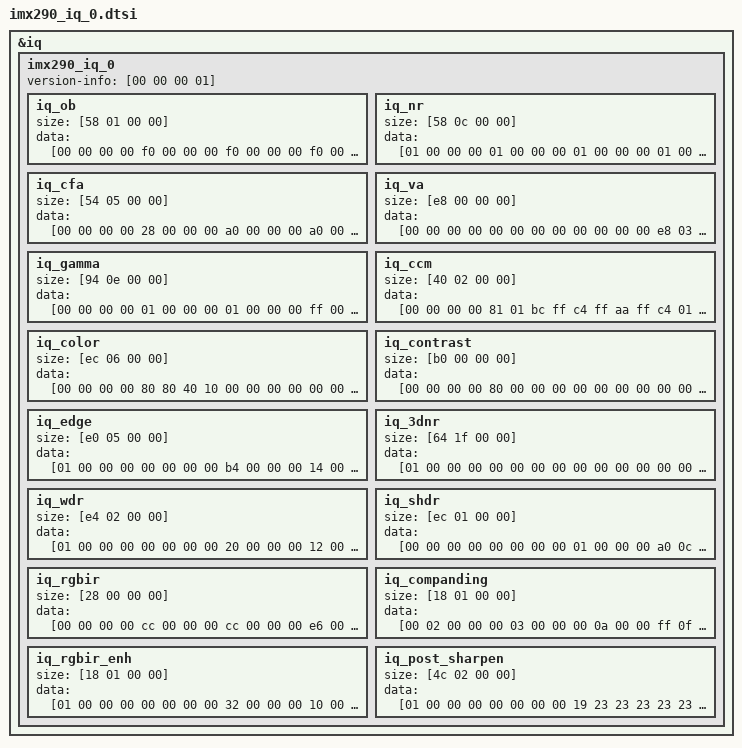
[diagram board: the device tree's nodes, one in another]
/*
 * Novatek Ltd. NVT9856x ISP part of dts
 */

&iq {
	imx290_iq_0 {
		version-info = [00 00 00 01];
		iq_ob {
			size = [58 01 00 00];
			data = [00 00 00 00 f0 00 00 00 f0 00 00 00 f0 00 00 00 f0 00 00 00 f0 00 00 00 f0 00 00 00 f0 00 00 00 f0 00 00 00 f0 00 00 00 f0 00 00 00 f0 00 00 00 f0 00 00 00 f0 00 00 00 f0 00 00 00 f0 00 00 00 f0 00 00 00 f0 00 00 00 f0 00 00 00 f0 00 00 00 f0 00 00 00 f0 00 00 00 f0 00 00 00 f0 00 00 00 f0 00 00 00 f0 00 00 00 f0 00 00 00 f0 00 00 00 f0 00 00 00 f0 00 00 00 f0 00 00 00 f0 00 00 00 f0 00 00 00 f0 00 00 00 f0 00 00 00 f0 00 00 00 f0 00 00 00 f0 00 00 00 f0 00 00 00 f0 00 00 00 f0 00 00 00 f0 00 00 00 f0 00 00 00 f0 00 00 00 f0 00 00 00 f0 00 00 00 f0 00 00 00 f0 00 00 00 f0 00 00 00 f0 00 00 00 f0 00 00 00 f0 00 00 00 f0 00 00 00 f0 00 00 00 f0 00 00 00 f0 00 00 00 f0 00 00 00 f0 00 00 00 f0 00 00 00 f0 00 00 00 f0 00 00 00 f0 00 00 00 f0 00 00 00 f0 00 00 00 f0 00 00 00 f0 00 00 00 f0 00 00 00 f0 00 00 00 f0 00 00 00 f0 00 00 00 f0 00 00 00 f0 00 00 00 f0 00 00 00 f0 00 00 00 f0 00 00 00 f0 00 00 00 f0 00 00 00 f0 00 00 00 f0 00 00 00 f0 00 00 00 f0 00 00 00 f0 00 00 00 f0 00 00 00 f0 00 00 00 f0 00 00 00 f0 00 00 00];
		};
		iq_nr {
			size = [58 0c 00 00];
			data = [01 00 00 00 01 00 00 00 01 00 00 00 01 00 00 00 01 00 00 00 00 00 00 00 00 00 00 00 00 01 00 00 00 00 00 00 ff 0f 00 00 ff 0f 00 00 ff 0f 00 00 ff 0f 00 00 ff 0f 00 00 ff 0f 00 00 ff 0f 00 00 ff 0f 00 00 ff 0f 00 00 ff 0f 00 00 00 01 80 00 00 00 00 00 00 00 00 00 00 00 00 00 00 00 00 00 00 00 00 00 00 00 00 00 00 00 00 00 00 00 00 00 00 00 00 00 00 00 00 00 00 00 00 00 00 00 00 00 00 00 00 00 00 00 00 00 00 00 00 00 00 00 00 00 00 00 00 00 00 00 00 00 00 00 00 00 00 00 00 00 00 00 00 00 00 00 00 00 00 00 00 00 00 00 00 00 00 00 00 00 80 00 00 00 00 00 00 00 00 00 00 00 00 00 00 00 00 00 00 00 00 00 00 00 00 00 00 00 02 00 00 00 02 00 00 00 00 00 00 00 c6 02 00 00 0c 04 00 00 af 06 00 00 3d 09 00 00 41 0f 00 00 c6 02 00 00 0c 04 00 00 af 06 00 00 3d 09 00 00 41 0f 00 00 00 00 80 00 00 00 00 00 00 00 00 00 00 00 00 00 00 00 00 00 00 00 00 00 00 00 00 00 00 00 00 00 00 00 00 00 00 00 00 00 00 00 00 00 00 00 00 00 00 00 00 00 00 00 00 00 00 00 00 00 00 00 00 00 00 00 00 00 00 00 00 00 00 00 00 00 00 00 00 00 00 00 00 00 00 00 00 00 00 00 00 00 00 00 00 00 00 00 00 00 00 00 00 00 80 00 00 00 08 00 00 00 08 00 00 00 08 00 00 00 08 00 00 00 00 00 00 00 04 00 00 00 00 00 00 00 00 00 00 00 00 00 00 00 c6 02 00 00 0c 04 00 00 af 06 00 00 3d 09 00 00 41 0f 00 00 c6 02 00 00 0c 04 00 00 af 06 00 00 3d 09 00 00 41 0f 00 00 00 00 80 00 00 00 00 00 00 00 00 00 01 00 00 00 01 00 00 00 01 00 00 00 02 00 00 00 00 00 00 00 00 00 00 00 01 00 00 00 01 00 00 00 01 00 00 00 01 00 00 00 01 00 00 00 02 00 00 00 02 00 00 00 02 00 00 00 02 00 00 00 02 00 00 00 02 00 00 00 02 00 00 00 02 00 00 00 03 00 00 00 03 00 00 00 00 00 00 00 00 00 00 00 80 00 00 00 08 00 00 00 08 00 00 00 08 00 00 00 08 00 00 00 00 00 00 00 04 00 00 00 00 00 00 00 00 00 00 00 00 00 00 00 c6 02 00 00 0c 04 00 00 af 06 00 00 3d 09 00 00 41 0f 00 00 c6 02 00 00 0c 04 00 00 af 06 00 00 3d 09 00 00 41 0f 00 00 00 00 80 00 00 00 00 00 01 00 00 00 02 00 00 00 03 00 00 00 03 00 00 00 04 00 00 00 00 00 00 00 01 00 00 00 02 00 00 00 02 00 00 00 03 00 00 00 03 00 00 00 03 00 00 00 04 00 00 00 04 00 00 00 04 00 00 00 05 00 00 00 05 00 00 00 05 00 00 00 05 00 00 00 05 00 00 00 06 00 00 00 06 00 00 00 00 00 00 00 00 00 00 00 80 00 00 00 08 00 00 00 08 00 00 00 08 00 00 00 08 00 00 00 00 00 00 00 04 00 00 00 00 00 00 00 00 00 00 00 00 00 00 00 c6 02 00 00 0c 04 00 00 af 06 00 00 3d 09 00 00 41 0f 00 00 c6 02 00 00 0c 04 00 00 af 06 00 00 3d 09 00 00 41 0f 00 00 00 00 80 00 00 00 00 00 01 00 00 00 02 00 00 00 03 00 00 00 03 00 00 00 04 00 00 00 00 00 00 00 01 00 00 00 02 00 00 00 02 00 00 00 03 00 00 00 03 00 00 00 03 00 00 00 04 00 00 00 04 00 00 00 04 00 00 00 05 00 00 00 05 00 00 00 05 00 00 00 05 00 00 00 05 00 00 00 06 00 00 00 06 00 00 00 00 00 00 00 00 00 00 00 80 00 00 00 08 00 00 00 08 00 00 00 08 00 00 00 08 00 00 00 00 00 00 00 08 00 00 00 00 00 00 00 00 00 00 00 00 00 00 00 c6 02 00 00 0c 04 00 00 af 06 00 00 3d 09 00 00 41 0f 00 00 c6 02 00 00 0c 04 00 00 af 06 00 00 3d 09 00 00 41 0f 00 00 00 00 80 00 00 00 00 00 02 00 00 00 03 00 00 00 04 00 00 00 04 00 00 00 06 00 00 00 00 00 00 00 01 00 00 00 02 00 00 00 02 00 00 00 03 00 00 00 03 00 00 00 03 00 00 00 04 00 00 00 04 00 00 00 04 00 00 00 05 00 00 00 05 00 00 00 05 00 00 00 05 00 00 00 05 00 00 00 06 00 00 00 06 00 00 00 00 00 00 00 10 00 00 00 80 00 00 00 08 00 00 00 08 00 00 00 08 00 00 00 08 00 00 00 00 00 00 00 0c 00 00 00 00 00 00 00 00 00 00 00 00 00 00 00 c6 02 00 00 0c 04 00 00 af 06 00 00 3d 09 00 00 41 0f 00 00 c6 02 00 00 0c 04 00 00 af 06 00 00 3d 09 00 00 41 0f 00 00 00 00 80 00 00 00 00 00 03 00 00 00 04 00 00 00 06 00 00 00 07 00 00 00 09 00 00 00 00 00 00 00 02 00 00 00 03 00 00 00 04 00 00 00 05 00 00 00 06 00 00 00 06 00 00 00 07 00 00 00 07 00 00 00 08 00 00 00 08 00 00 00 09 00 00 00 09 00 00 00 0a 00 00 00 0a 00 00 00 0a 00 00 00 0b 00 00 00 00 00 00 00 10 00 00 00 80 00 00 00 08 00 00 00 08 00 00 00 08 00 00 00 08 00 00 00 00 00 00 00 10 00 00 00 00 00 00 00 00 00 00 00 00 00 00 00 c6 02 00 00 0c 04 00 00 af 06 00 00 3d 09 00 00 41 0f 00 00 c6 02 00 00 0c 04 00 00 af 06 00 00 3d 09 00 00 41 0f 00 00 00 00 80 00 00 00 00 00 07 00 00 00 09 00 00 00 0c 00 00 00 0e 00 00 00 13 00 00 00 00 00 00 00 05 00 00 00 07 00 00 00 09 00 00 00 0a 00 00 00 0b 00 00 00 0c 00 00 00 0d 00 00 00 0e 00 00 00 0f 00 00 00 10 00 00 00 11 00 00 00 12 00 00 00 12 00 00 00 13 00 00 00 14 00 00 00 14 00 00 00 00 00 00 00 10 00 00 00 80 00 00 00 08 00 00 00 08 00 00 00 08 00 00 00 08 00 00 00 00 00 00 00 12 00 00 00 00 00 00 00 00 00 00 00 00 00 00 00 c6 02 00 00 0c 04 00 00 af 06 00 00 3d 09 00 00 41 0f 00 00 c6 02 00 00 0c 04 00 00 af 06 00 00 3d 09 00 00 41 0f 00 00 00 00 80 00 00 00 00 00 0b 00 00 00 10 00 00 00 14 00 00 00 17 00 00 00 21 00 00 00 00 00 00 00 08 00 00 00 0b 00 00 00 0d 00 00 00 10 00 00 00 11 00 00 00 13 00 00 00 15 00 00 00 16 00 00 00 18 00 00 00 19 00 00 00 1a 00 00 00 1b 00 00 00 1c 00 00 00 1d 00 00 00 1e 00 00 00 20 00 00 00 00 00 00 00 10 00 00 00 80 00 00 00 08 00 00 00 08 00 00 00 08 00 00 00 08 00 00 00 00 00 00 00 12 00 00 00 00 00 00 00 00 00 00 00 00 00 00 00 c6 02 00 00 0c 04 00 00 af 06 00 00 3d 09 00 00 41 0f 00 00 c6 02 00 00 0c 04 00 00 af 06 00 00 3d 09 00 00 41 0f 00 00 2c 01 2c 01 00 00 00 00 20 00 00 00 2d 00 00 00 38 00 00 00 40 00 00 00 5b 00 00 00 00 00 00 00 16 00 00 00 1f 00 00 00 26 00 00 00 2c 00 00 00 31 00 00 00 35 00 00 00 3a 00 00 00 3e 00 00 00 42 00 00 00 45 00 00 00 48 00 00 00 4c 00 00 00 4f 00 00 00 52 00 00 00 55 00 00 00 58 00 00 00 08 00 00 00 12 00 00 00 80 00 00 00 08 00 00 00 08 00 00 00 08 00 00 00 08 00 00 00 00 00 00 00 14 00 00 00 00 00 00 00 00 00 00 00 00 00 00 00 c6 02 00 00 0c 04 00 00 af 06 00 00 3d 09 00 00 41 0f 00 00 c6 02 00 00 0c 04 00 00 af 06 00 00 3d 09 00 00 41 0f 00 00 00 00 80 00 00 00 00 00 31 00 00 00 46 00 00 00 56 00 00 00 63 00 00 00 8d 00 00 00 00 00 00 00 22 00 00 00 30 00 00 00 3a 00 00 00 44 00 00 00 4c 00 00 00 53 00 00 00 59 00 00 00 60 00 00 00 66 00 00 00 6b 00 00 00 70 00 00 00 75 00 00 00 7a 00 00 00 7f 00 00 00 83 00 00 00 88 00 00 00 0f 00 00 00 12 00 00 00 80 00 00 00 08 00 00 00 08 00 00 00 08 00 00 00 08 00 00 00 00 00 00 00 18 00 00 00 00 00 00 00 00 00 00 00 00 00 00 00 c6 02 00 00 0c 04 00 00 af 06 00 00 3d 09 00 00 41 0f 00 00 c6 02 00 00 0c 04 00 00 af 06 00 00 3d 09 00 00 41 0f 00 00 00 00 80 00 00 00 00 00 43 00 00 00 5f 00 00 00 75 00 00 00 87 00 00 00 bf 00 00 00 00 00 00 00 30 00 00 00 43 00 00 00 53 00 00 00 60 00 00 00 6b 00 00 00 75 00 00 00 7e 00 00 00 87 00 00 00 90 00 00 00 97 00 00 00 9f 00 00 00 a6 00 00 00 ad 00 00 00 b3 00 00 00 b9 00 00 00 c0 00 00 00 0f 00 00 00 12 00 00 00 80 00 00 00 08 00 00 00 08 00 00 00 08 00 00 00 08 00 00 00 00 00 00 00 1a 00 00 00 01 00 00 00 02 00 00 00 00 00 00 00 c6 02 00 00 0c 04 00 00 af 06 00 00 3d 09 00 00 41 0f 00 00 c6 02 00 00 0c 04 00 00 af 06 00 00 3d 09 00 00 41 0f 00 00 00 00 80 00 00 00 00 00 5e 00 00 00 85 00 00 00 a3 00 00 00 bc 00 00 00 0a 01 00 00 00 00 00 00 40 00 00 00 5a 00 00 00 6e 00 00 00 80 00 00 00 8f 00 00 00 9c 00 00 00 a9 00 00 00 b5 00 00 00 c0 00 00 00 ca 00 00 00 d4 00 00 00 dd 00 00 00 e6 00 00 00 ef 00 00 00 f7 00 00 00 00 01 00 00 0f 00 00 00 00 00 00 00 80 00 00 00 08 00 00 00 08 00 00 00 08 00 00 00 08 00 00 00 00 00 00 00 1c 00 00 00 02 00 00 00 03 00 00 00 00 00 00 00 c6 02 00 00 0c 04 00 00 af 06 00 00 3d 09 00 00 41 0f 00 00 c6 02 00 00 0c 04 00 00 af 06 00 00 3d 09 00 00 41 0f 00 00 09 00 80 00 00 00 00 00 2e 00 00 00 42 00 00 00 51 00 00 00 5d 00 00 00 84 00 00 00 00 00 00 00 32 00 00 00 47 00 00 00 57 00 00 00 65 00 00 00 71 00 00 00 7c 00 00 00 86 00 00 00 8f 00 00 00 98 00 00 00 a0 00 00 00 a8 00 00 00 af 00 00 00 b7 00 00 00 be 00 00 00 c4 00 00 00 cb 00 00 00 00 00 00 00 20 00 00 00 20 00 00 00 10 00 00 00 10 00 00 00 10 00 00 00 10 00 00 00 1c 00 00 00 16 00 00 00 01 00 00 00 01 00 00 00 00 00 00 00 c6 02 00 00 0c 04 00 00 af 06 00 00 3d 09 00 00 41 0f 00 00 c6 02 00 00 0c 04 00 00 af 06 00 00 3d 09 00 00 41 0f 00 00 09 00 80 00 00 00 00 00 2e 00 00 00 42 00 00 00 51 00 00 00 5d 00 00 00 84 00 00 00 00 00 00 00 32 00 00 00 47 00 00 00 57 00 00 00 65 00 00 00 71 00 00 00 7c 00 00 00 86 00 00 00 8f 00 00 00 98 00 00 00 a0 00 00 00 a8 00 00 00 af 00 00 00 b7 00 00 00 be 00 00 00 c4 00 00 00 cb 00 00 00 00 00 00 00 20 00 00 00 20 00 00 00 10 00 00 00 10 00 00 00 10 00 00 00 10 00 00 00 1c 00 00 00 16 00 00 00 01 00 00 00 01 00 00 00 00 00 00 00 c6 02 00 00 0c 04 00 00 af 06 00 00 3d 09 00 00 41 0f 00 00 c6 02 00 00 0c 04 00 00 af 06 00 00 3d 09 00 00 41 0f 00 00 09 00 80 00 00 00 00 00 2e 00 00 00 42 00 00 00 51 00 00 00 5d 00 00 00 84 00 00 00 00 00 00 00 32 00 00 00 47 00 00 00 57 00 00 00 65 00 00 00 71 00 00 00 7c 00 00 00 86 00 00 00 8f 00 00 00 98 00 00 00 a0 00 00 00 a8 00 00 00 af 00 00 00 b7 00 00 00 be 00 00 00 c4 00 00 00 cb 00 00 00 00 00 00 00 20 00 00 00 20 00 00 00 10 00 00 00 10 00 00 00 10 00 00 00 10 00 00 00 1c 00 00 00 16 00 00 00 01 00 00 00 01 00 00 00 00 00 00 00 c6 02 00 00 0c 04 00 00 af 06 00 00 3d 09 00 00 41 0f 00 00 c6 02 00 00 0c 04 00 00 af 06 00 00 3d 09 00 00 41 0f 00 00 09 00 80 00 00 00 00 00 2e 00 00 00 42 00 00 00 51 00 00 00 5d 00 00 00 84 00 00 00 00 00 00 00 32 00 00 00 47 00 00 00 57 00 00 00 65 00 00 00 71 00 00 00 7c 00 00 00 86 00 00 00 8f 00 00 00 98 00 00 00 a0 00 00 00 a8 00 00 00 af 00 00 00 b7 00 00 00 be 00 00 00 c4 00 00 00 cb 00 00 00 00 00 00 00 20 00 00 00 20 00 00 00 10 00 00 00 10 00 00 00 10 00 00 00 10 00 00 00 1c 00 00 00 16 00 00 00 01 00 00 00 01 00 00 00];
		};
		iq_cfa {
			size = [54 05 00 00];
			data = [00 00 00 00 28 00 00 00 a0 00 00 00 a0 00 00 00 40 00 00 00 0f 00 00 00 0f 00 00 00 07 00 00 00 04 00 00 00 03 00 00 00 02 00 00 00 02 00 00 00 01 00 00 00 01 00 00 00 01 00 00 00 01 00 00 00 00 00 00 00 00 00 00 00 00 00 00 00 00 00 00 00 00 00 00 00 28 00 00 00 a0 00 00 00 a0 00 00 00 40 00 00 00 0f 00 00 00 0f 00 00 00 07 00 00 00 04 00 00 00 03 00 00 00 02 00 00 00 02 00 00 00 01 00 00 00 01 00 00 00 01 00 00 00 01 00 00 00 00 00 00 00 00 00 00 00 00 00 00 00 00 00 00 00 00 00 00 00 28 00 00 00 a0 00 00 00 a0 00 00 00 40 00 00 00 0f 00 00 00 0f 00 00 00 07 00 00 00 04 00 00 00 03 00 00 00 02 00 00 00 02 00 00 00 01 00 00 00 01 00 00 00 01 00 00 00 01 00 00 00 00 00 00 00 00 00 00 00 00 00 00 00 00 00 00 00 00 00 00 00 28 00 00 00 a0 00 00 00 a0 00 00 00 40 00 00 00 0f 00 00 00 0f 00 00 00 07 00 00 00 04 00 00 00 03 00 00 00 02 00 00 00 02 00 00 00 01 00 00 00 01 00 00 00 01 00 00 00 01 00 00 00 00 00 00 00 00 00 00 00 00 00 00 00 00 00 00 00 00 00 00 00 28 00 00 00 a0 00 00 00 a0 00 00 00 40 00 00 00 0f 00 00 00 0f 00 00 00 07 00 00 00 04 00 00 00 03 00 00 00 02 00 00 00 02 00 00 00 01 00 00 00 01 00 00 00 01 00 00 00 01 00 00 00 00 00 00 00 00 00 00 00 00 00 00 00 00 00 00 00 00 00 00 00 28 00 00 00 a0 00 00 00 a0 00 00 00 40 00 00 00 0f 00 00 00 0f 00 00 00 07 00 00 00 04 00 00 00 03 00 00 00 02 00 00 00 02 00 00 00 01 00 00 00 01 00 00 00 01 00 00 00 01 00 00 00 00 00 00 00 00 00 00 00 00 00 00 00 00 00 00 00 00 00 00 00 28 00 00 00 a0 00 00 00 a0 00 00 00 40 00 00 00 0f 00 00 00 0f 00 00 00 07 00 00 00 04 00 00 00 03 00 00 00 02 00 00 00 02 00 00 00 01 00 00 00 01 00 00 00 01 00 00 00 01 00 00 00 00 00 00 00 00 00 00 00 00 00 00 00 00 00 00 00 00 00 00 00 28 00 00 00 a0 00 00 00 a0 00 00 00 40 00 00 00 0f 00 00 00 0f 00 00 00 07 00 00 00 04 00 00 00 03 00 00 00 02 00 00 00 02 00 00 00 01 00 00 00 01 00 00 00 01 00 00 00 01 00 00 00 00 00 00 00 00 00 00 00 00 00 00 00 00 00 00 00 00 00 00 00 28 00 00 00 a0 00 00 00 a0 00 00 00 40 00 00 00 0f 00 00 00 0f 00 00 00 07 00 00 00 04 00 00 00 03 00 00 00 02 00 00 00 02 00 00 00 01 00 00 00 01 00 00 00 01 00 00 00 01 00 00 00 00 00 00 00 00 00 00 00 00 00 00 00 00 00 00 00 00 00 00 00 50 00 00 00 a0 00 00 00 40 01 00 00 40 00 00 00 0f 00 00 00 0f 00 00 00 07 00 00 00 04 00 00 00 03 00 00 00 02 00 00 00 02 00 00 00 01 00 00 00 01 00 00 00 01 00 00 00 01 00 00 00 00 00 00 00 00 00 00 00 00 00 00 00 00 00 00 00 00 00 00 00 78 00 00 00 a0 00 00 00 80 02 00 00 40 00 00 00 0f 00 00 00 0f 00 00 00 07 00 00 00 04 00 00 00 03 00 00 00 02 00 00 00 02 00 00 00 01 00 00 00 01 00 00 00 01 00 00 00 01 00 00 00 00 00 00 00 00 00 00 00 00 00 00 00 00 00 00 00 00 00 00 00 78 00 00 00 a0 00 00 00 80 02 00 00 20 00 00 00 08 00 00 00 08 00 00 00 03 00 00 00 02 00 00 00 01 00 00 00 01 00 00 00 01 00 00 00 00 00 00 00 00 00 00 00 00 00 00 00 00 00 00 00 00 00 00 00 00 00 00 00 00 00 00 00 00 00 00 00 00 00 00 00 78 00 00 00 a0 00 00 00 80 02 00 00 20 00 00 00 08 00 00 00 08 00 00 00 03 00 00 00 02 00 00 00 01 00 00 00 01 00 00 00 01 00 00 00 00 00 00 00 00 00 00 00 00 00 00 00 00 00 00 00 00 00 00 00 00 00 00 00 00 00 00 00 00 00 00 00 00 00 00 00 78 00 00 00 a0 00 00 00 80 02 00 00 20 00 00 00 08 00 00 00 08 00 00 00 03 00 00 00 02 00 00 00 01 00 00 00 01 00 00 00 01 00 00 00 00 00 00 00 00 00 00 00 00 00 00 00 00 00 00 00 00 00 00 00 00 00 00 00 00 00 00 00 00 00 00 00 00 00 00 00 78 00 00 00 a0 00 00 00 80 02 00 00 20 00 00 00 08 00 00 00 08 00 00 00 03 00 00 00 02 00 00 00 01 00 00 00 01 00 00 00 01 00 00 00 00 00 00 00 00 00 00 00 00 00 00 00 00 00 00 00 00 00 00 00 00 00 00 00 00 00 00 00 00 00 00 00 00 00 00 00 78 00 00 00 a0 00 00 00 80 02 00 00 20 00 00 00 08 00 00 00 08 00 00 00 03 00 00 00 02 00 00 00 01 00 00 00 01 00 00 00 01 00 00 00 00 00 00 00 00 00 00 00 00 00 00 00 00 00 00 00 00 00 00 00 00 00 00 00 00 00 00 00 00 00 00 00 00 00 00 00 78 00 00 00 a0 00 00 00 80 02 00 00 20 00 00 00 08 00 00 00 08 00 00 00 03 00 00 00 02 00 00 00 01 00 00 00 01 00 00 00 01 00 00 00 00 00 00 00 00 00 00 00 00 00 00 00 00 00 00 00 00 00 00 00 00 00 00 00 00 00 00 00 00 00 00 00 00 00 00 00];
		};
		iq_va {
			size = [e8 00 00 00];
			data = [00 00 00 00 00 00 00 00 00 00 00 00 e8 03 00 00 e8 03 00 00 00 00 00 00 00 00 00 00 e8 03 00 00 e8 03 00 00 00 00 00 00 00 00 00 00 e8 03 00 00 e8 03 00 00 00 00 00 00 00 00 00 00 e8 03 00 00 e8 03 00 00 00 00 00 00 00 00 00 00 e8 03 00 00 e8 03 00 00 02 ff 00 00 03 02 00 ff 00 03 06 00 08 00 06 00 08 00 06 00 08 00 06 00 08 00 06 00 08 00 06 00 08 00 06 00 08 00 06 00 08 00 06 00 08 00 06 00 08 00 06 00 08 00 06 00 08 00 06 00 08 00 06 00 08 00 06 00 08 00 06 00 08 00 06 00 08 00 06 00 08 00 06 00 08 00 06 00 08 00 06 00 08 00 06 00 08 00 06 00 08 00 06 00 08 00 06 00 08 00 06 00 08 00 06 00 08 00 06 00 08 00 06 00 08 00 06 00 08 00 06 00 08 00 06 00 08 00 06 00 08 00 06 00 08 00 00 00];
		};
		iq_gamma {
			size = [94 0e 00 00];
			data = [00 00 00 00 01 00 00 00 01 00 00 00 ff 00 00 00 ff 00 00 00 ff 00 00 00 ff 00 00 00 ff 00 00 00 ff 00 00 00 ff 00 00 00 ff 00 00 00 ff 00 00 00 ff 00 00 00 ff 00 00 00 ff 00 00 00 ff 00 00 00 ff 00 00 00 ff 00 00 00 ff 00 00 00 ff 00 00 00 00 00 00 00 08 00 00 00 10 00 00 00 18 00 00 00 1c 00 00 00 20 00 00 00 24 00 00 00 26 00 00 00 28 00 00 00 29 00 00 00 2a 00 00 00 2b 00 00 00 2c 00 00 00 2d 00 00 00 2e 00 00 00 2f 00 00 00 30 00 00 00 31 00 00 00 32 00 00 00 33 00 00 00 34 00 00 00 35 00 00 00 36 00 00 00 37 00 00 00 38 00 00 00 39 00 00 00 3a 00 00 00 3b 00 00 00 3c 00 00 00 3d 00 00 00 3e 00 00 00 3f 00 00 00 03 00 00 00 03 00 00 00 03 00 00 00 02 00 00 00 02 00 00 00 02 00 00 00 01 00 00 00 01 00 00 00 00 00 00 00 00 00 00 00 00 00 00 00 00 00 00 00 00 00 00 00 00 00 00 00 00 00 00 00 00 00 00 00 00 00 00 00 00 00 00 00 00 00 00 00 00 00 00 00 00 00 00 00 00 00 00 00 00 00 00 00 00 00 00 00 00 00 00 00 00 00 00 00 00 00 00 00 00 00 00 00 00 00 00 00 00 00 00 00 00 00 00 00 00 00 00 00 00 00 00 00 10 00 00 00 20 00 00 00 30 00 00 00 40 00 00 00 50 00 00 00 60 00 00 00 70 00 00 00 80 00 00 00 90 00 00 00 a0 00 00 00 b0 00 00 00 c0 00 00 00 d0 00 00 00 e0 00 00 00 f0 00 00 00 00 01 00 00 10 01 00 00 20 01 00 00 30 01 00 00 40 01 00 00 50 01 00 00 60 01 00 00 70 01 00 00 80 01 00 00 a0 01 00 00 c0 01 00 00 e0 01 00 00 00 02 00 00 20 02 00 00 40 02 00 00 60 02 00 00 80 02 00 00 a0 02 00 00 c0 02 00 00 e0 02 00 00 00 03 00 00 40 03 00 00 80 03 00 00 c0 03 00 00 00 04 00 00 80 04 00 00 00 05 00 00 80 05 00 00 00 06 00 00 80 06 00 00 00 07 00 00 80 07 00 00 00 08 00 00 80 08 00 00 00 09 00 00 80 09 00 00 00 0a 00 00 80 0a 00 00 00 0b 00 00 80 0b 00 00 00 0c 00 00 80 0c 00 00 00 0d 00 00 80 0d 00 00 00 0e 00 00 80 0e 00 00 00 0f 00 00 80 0f 00 00 ff 0f 00 00 00 00 00 00 04 00 00 00 08 00 00 00 0c 00 00 00 10 00 00 00 14 00 00 00 18 00 00 00 1a 00 00 00 1c 00 00 00 1d 00 00 00 1e 00 00 00 1f 00 00 00 20 00 00 00 21 00 00 00 22 00 00 00 23 00 00 00 24 00 00 00 25 00 00 00 26 00 00 00 27 00 00 00 28 00 00 00 29 00 00 00 2a 00 00 00 2b 00 00 00 2c 00 00 00 2d 00 00 00 2e 00 00 00 2f 00 00 00 30 00 00 00 34 00 00 00 38 00 00 00 3c 00 00 00 02 00 00 00 02 00 00 00 02 00 00 00 02 00 00 00 02 00 00 00 02 00 00 00 01 00 00 00 01 00 00 00 00 00 00 00 00 00 00 00 00 00 00 00 00 00 00 00 00 00 00 00 00 00 00 00 00 00 00 00 00 00 00 00 00 00 00 00 00 00 00 00 00 00 00 00 00 00 00 00 00 00 00 00 00 00 00 00 00 00 00 00 00 00 00 00 00 00 00 00 00 00 00 00 00 00 00 00 00 00 00 00 02 00 00 00 02 00 00 00 02 00 00 00 02 00 00 00 05 00 00 00 00 00 00 00 00 00 00 00 80 00 00 00 f7 00 00 00 67 01 00 00 d0 01 00 00 30 02 00 00 82 02 00 00 be 02 00 00 f7 02 00 00 27 03 00 00 56 03 00 00 84 03 00 00 b2 03 00 00 de 03 00 00 09 04 00 00 33 04 00 00 5c 04 00 00 84 04 00 00 ac 04 00 00 d3 04 00 00 f9 04 00 00 1f 05 00 00 43 05 00 00 67 05 00 00 8b 05 00 00 d1 05 00 00 15 06 00 00 58 06 00 00 99 06 00 00 17 07 00 00 90 07 00 00 06 08 00 00 78 08 00 00 e7 08 00 00 54 09 00 00 be 09 00 00 26 0a 00 00 8d 0a 00 00 f1 0a 00 00 55 0b 00 00 b6 0b 00 00 17 0c 00 00 76 0c 00 00 d4 0c 00 00 32 0d 00 00 8e 0d 00 00 e9 0d 00 00 44 0e 00 00 9e 0e 00 00 b5 0e 00 00 cb 0e 00 00 e1 0e 00 00 f7 0e 00 00 0e 0f 00 00 24 0f 00 00 3a 0f 00 00 50 0f 00 00 66 0f 00 00 7c 0f 00 00 92 0f 00 00 a8 0f 00 00 be 0f 00 00 d4 0f 00 00 e9 0f 00 00 ff 0f 00 00 19 00 00 00 00 00 00 00 9e 00 00 00 2e 01 00 00 b1 01 00 00 2a 02 00 00 9a 02 00 00 01 03 00 00 63 03 00 00 be 03 00 00 14 04 00 00 65 04 00 00 b3 04 00 00 fc 04 00 00 41 05 00 00 84 05 00 00 c4 05 00 00 02 06 00 00 3a 06 00 00 71 06 00 00 a6 06 00 00 d9 06 00 00 09 07 00 00 38 07 00 00 64 07 00 00 8f 07 00 00 d3 07 00 00 16 08 00 00 57 08 00 00 96 08 00 00 0d 09 00 00 7d 09 00 00 e5 09 00 00 46 0a 00 00 a6 0a 00 00 02 0b 00 00 59 0b 00 00 ac 0b 00 00 fe 0b 00 00 4d 0c 00 00 9a 0c 00 00 e5 0c 00 00 2f 0d 00 00 77 0d 00 00 bd 0d 00 00 02 0e 00 00 45 0e 00 00 87 0e 00 00 c8 0e 00 00 08 0f 00 00 18 0f 00 00 28 0f 00 00 38 0f 00 00 48 0f 00 00 57 0f 00 00 67 0f 00 00 76 0f 00 00 85 0f 00 00 95 0f 00 00 a4 0f 00 00 b4 0f 00 00 c3 0f 00 00 d2 0f 00 00 e1 0f 00 00 f0 0f 00 00 ff 0f 00 00 32 00 00 00 00 00 00 00 e0 00 00 00 9e 01 00 00 43 02 00 00 d5 02 00 00 58 03 00 00 cf 03 00 00 3b 04 00 00 9e 04 00 00 fb 04 00 00 51 05 00 00 a1 05 00 00 ed 05 00 00 33 06 00 00 77 06 00 00 b7 06 00 00 f5 06 00 00 2c 07 00 00 61 07 00 00 95 07 00 00 c6 07 00 00 f4 07 00 00 21 08 00 00 4b 08 00 00 74 08 00 00 b3 08 00 00 f1 08 00 00 2d 09 00 00 67 09 00 00 d4 09 00 00 3a 0a 00 00 98 0a 00 00 ee 0a 00 00 44 0b 00 00 96 0b 00 00 e4 0b 00 00 2e 0c 00 00 76 0c 00 00 bc 0c 00 00 01 0d 00 00 43 0d 00 00 84 0d 00 00 c3 0d 00 00 01 0e 00 00 3e 0e 00 00 7a 0e 00 00 b4 0e 00 00 ed 0e 00 00 26 0f 00 00 34 0f 00 00 42 0f 00 00 4f 0f 00 00 5d 0f 00 00 6b 0f 00 00 79 0f 00 00 86 0f 00 00 94 0f 00 00 a2 0f 00 00 af 0f 00 00 bc 0f 00 00 ca 0f 00 00 d7 0f 00 00 e4 0f 00 00 f2 0f 00 00 ff 0f 00 00 4b 00 00 00 00 00 00 00 70 01 00 00 70 02 00 00 39 03 00 00 df 03 00 00 6d 04 00 00 ea 04 00 00 59 05 00 00 be 05 00 00 19 06 00 00 6d 06 00 00 ba 06 00 00 03 07 00 00 41 07 00 00 7d 07 00 00 b5 07 00 00 ec 07 00 00 1c 08 00 00 4b 08 00 00 78 08 00 00 a4 08 00 00 cd 08 00 00 f5 08 00 00 1b 09 00 00 41 09 00 00 7f 09 00 00 bb 09 00 00 f4 09 00 00 2a 0a 00 00 91 0a 00 00 f0 0a 00 00 47 0b 00 00 95 0b 00 00 e2 0b 00 00 2c 0c 00 00 72 0c 00 00 b4 0c 00 00 f4 0c 00 00 32 0d 00 00 6f 0d 00 00 a9 0d 00 00 e1 0d 00 00 18 0e 00 00 4d 0e 00 00 82 0e 00 00 b5 0e 00 00 e7 0e 00 00 17 0f 00 00 47 0f 00 00 53 0f 00 00 5f 0f 00 00 6a 0f 00 00 76 0f 00 00 82 0f 00 00 8e 0f 00 00 99 0f 00 00 a5 0f 00 00 b0 0f 00 00 bb 0f 00 00 c6 0f 00 00 d2 0f 00 00 dd 0f 00 00 e8 0f 00 00 f4 0f 00 00 ff 0f 00 00 64 00 00 00 00 00 00 00 00 02 00 00 43 03 00 00 2f 04 00 00 e9 04 00 00 83 05 00 00 06 06 00 00 78 06 00 00 de 06 00 00 37 07 00 00 89 07 00 00 d4 07 00 00 19 08 00 00 4f 08 00 00 83 08 00 00 b4 08 00 00 e4 08 00 00 0d 09 00 00 35 09 00 00 5c 09 00 00 82 09 00 00 a7 09 00 00 ca 09 00 00 ec 09 00 00 0e 0a 00 00 4c 0a 00 00 86 0a 00 00 bc 0a 00 00 ed 0a 00 00 4e 0b 00 00 a7 0b 00 00 f6 0b 00 00 3c 0c 00 00 81 0c 00 00 c2 0c 00 00 00 0d 00 00 3b 0d 00 00 73 0d 00 00 a9 0d 00 00 dd 0d 00 00 0f 0e 00 00 3e 0e 00 00 6d 0e 00 00 9a 0e 00 00 c6 0e 00 00 f0 0e 00 00 1a 0f 00 00 42 0f 00 00 69 0f 00 00 73 0f 00 00 7d 0f 00 00 86 0f 00 00 90 0f 00 00 9a 0f 00 00 a3 0f 00 00 ac 0f 00 00 b6 0f 00 00 bf 0f 00 00 c8 0f 00 00 d1 0f 00 00 db 0f 00 00 e4 0f 00 00 ed 0f 00 00 f6 0f 00 00 ff 0f 00 00 00 00 00 00 25 00 00 00 49 00 00 00 6b 00 00 00 8b 00 00 00 a9 00 00 00 c6 00 00 00 e1 00 00 00 f1 00 00 00 01 01 00 00 11 01 00 00 21 01 00 00 30 01 00 00 3e 01 00 00 4d 01 00 00 5b 01 00 00 68 01 00 00 75 01 00 00 82 01 00 00 8f 01 00 00 9b 01 00 00 a6 01 00 00 b1 01 00 00 bc 01 00 00 c7 01 00 00 d1 01 00 00 db 01 00 00 e4 01 00 00 ed 01 00 00 f6 01 00 00 fe 01 00 00 06 02 00 00 0d 02 00 00 14 02 00 00 1b 02 00 00 22 02 00 00 29 02 00 00 30 02 00 00 36 02 00 00 3d 02 00 00 44 02 00 00 4b 02 00 00 52 02 00 00 59 02 00 00 5f 02 00 00 66 02 00 00 6d 02 00 00 73 02 00 00 7a 02 00 00 80 02 00 00 87 02 00 00 8d 02 00 00 93 02 00 00 9a 02 00 00 a0 02 00 00 a6 02 00 00 ac 02 00 00 b3 02 00 00 b9 02 00 00 bf 02 00 00 c5 02 00 00 cb 02 00 00 d1 02 00 00 d7 02 00 00 dd 02 00 00 e3 02 00 00 e8 02 00 00 ee 02 00 00 f4 02 00 00 fa 02 00 00 ff 02 00 00 04 03 00 00 09 03 00 00 0e 03 00 00 13 03 00 00 18 03 00 00 1d 03 00 00 21 03 00 00 26 03 00 00 2b 03 00 00 30 03 00 00 35 03 00 00 3a 03 00 00 3e 03 00 00 43 03 00 00 48 03 00 00 4d 03 00 00 51 03 00 00 56 03 00 00 5b 03 00 00 5f 03 00 00 64 03 00 00 68 03 00 00 6d 03 00 00 72 03 00 00 76 03 00 00 7b 03 00 00 7f 03 00 00 84 03 00 00 88 03 00 00 8c 03 00 00 91 03 00 00 95 03 00 00 99 03 00 00 9e 03 00 00 a2 03 00 00 a6 03 00 00 ab 03 00 00 af 03 00 00 b3 03 00 00 b7 03 00 00 bb 03 00 00 bf 03 00 00 c4 03 00 00 c8 03 00 00 cc 03 00 00 d0 03 00 00 d4 03 00 00 d8 03 00 00 dc 03 00 00 e0 03 00 00 e4 03 00 00 e8 03 00 00 eb 03 00 00 ef 03 00 00 f3 03 00 00 f7 03 00 00 fb 03 00 00 ff 03 00 00 06 00 00 00 00 00 00 00 25 00 00 00 49 00 00 00 6b 00 00 00 8b 00 00 00 a9 00 00 00 c6 00 00 00 e1 00 00 00 f1 00 00 00 01 01 00 00 11 01 00 00 21 01 00 00 30 01 00 00 3e 01 00 00 4d 01 00 00 5b 01 00 00 68 01 00 00 75 01 00 00 82 01 00 00 8f 01 00 00 9b 01 00 00 a6 01 00 00 b1 01 00 00 bc 01 00 00 c7 01 00 00 d1 01 00 00 db 01 00 00 e4 01 00 00 ed 01 00 00 f6 01 00 00 fe 01 00 00 06 02 00 00 0d 02 00 00 14 02 00 00 1b 02 00 00 22 02 00 00 29 02 00 00 30 02 00 00 36 02 00 00 3d 02 00 00 44 02 00 00 4b 02 00 00 52 02 00 00 59 02 00 00 5f 02 00 00 66 02 00 00 6d 02 00 00 73 02 00 00 7a 02 00 00 80 02 00 00 87 02 00 00 8d 02 00 00 93 02 00 00 9a 02 00 00 a0 02 00 00 a6 02 00 00 ac 02 00 00 b3 02 00 00 b9 02 00 00 bf 02 00 00 c5 02 00 00 cb 02 00 00 d1 02 00 00 d7 02 00 00 dd 02 00 00 e3 02 00 00 e8 02 00 00 ee 02 00 00 f4 02 00 00 fa 02 00 00 ff 02 00 00 04 03 00 00 09 03 00 00 0e 03 00 00 13 03 00 00 18 03 00 00 1d 03 00 00 21 03 00 00 26 03 00 00 2b 03 00 00 30 03 00 00 35 03 00 00 3a 03 00 00 3e 03 00 00 43 03 00 00 48 03 00 00 4d 03 00 00 51 03 00 00 56 03 00 00 5b 03 00 00 5f 03 00 00 64 03 00 00 68 03 00 00 6d 03 00 00 72 03 00 00 76 03 00 00 7b 03 00 00 7f 03 00 00 84 03 00 00 88 03 00 00 8c 03 00 00 91 03 00 00 95 03 00 00 99 03 00 00 9e 03 00 00 a2 03 00 00 a6 03 00 00 ab 03 00 00 af 03 00 00 b3 03 00 00 b7 03 00 00 bb 03 00 00 bf 03 00 00 c4 03 00 00 c8 03 00 00 cc 03 00 00 d0 03 00 00 d4 03 00 00 d8 03 00 00 dc 03 00 00 e0 03 00 00 e4 03 00 00 e8 03 00 00 eb 03 00 00 ef 03 00 00 f3 03 00 00 f7 03 00 00 fb 03 00 00 ff 03 00 00 04 00 00 00 00 00 00 00 25 00 00 00 49 00 00 00 6b 00 00 00 8b 00 00 00 a9 00 00 00 c6 00 00 00 e1 00 00 00 f1 00 00 00 01 01 00 00 11 01 00 00 21 01 00 00 30 01 00 00 3e 01 00 00 4d 01 00 00 5b 01 00 00 68 01 00 00 75 01 00 00 82 01 00 00 8f 01 00 00 9b 01 00 00 a6 01 00 00 b1 01 00 00 bc 01 00 00 c7 01 00 00 d1 01 00 00 db 01 00 00 e4 01 00 00 ed 01 00 00 f6 01 00 00 fe 01 00 00 06 02 00 00 0d 02 00 00 14 02 00 00 1b 02 00 00 22 02 00 00 29 02 00 00 30 02 00 00 36 02 00 00 3d 02 00 00 44 02 00 00 4b 02 00 00 52 02 00 00 59 02 00 00 5f 02 00 00 66 02 00 00 6d 02 00 00 73 02 00 00 7a 02 00 00 80 02 00 00 87 02 00 00 8d 02 00 00 93 02 00 00 9a 02 00 00 a0 02 00 00 a6 02 00 00 ac 02 00 00 b3 02 00 00 b9 02 00 00 bf 02 00 00 c5 02 00 00 cb 02 00 00 d1 02 00 00 d7 02 00 00 dd 02 00 00 e3 02 00 00 e8 02 00 00 ee 02 00 00 f4 02 00 00 fa 02 00 00 ff 02 00 00 04 03 00 00 09 03 00 00 0e 03 00 00 13 03 00 00 18 03 00 00 1d 03 00 00 21 03 00 00 26 03 00 00 2b 03 00 00 30 03 00 00 35 03 00 00 3a 03 00 00 3e 03 00 00 43 03 00 00 48 03 00 00 4d 03 00 00 51 03 00 00 56 03 00 00 5b 03 00 00 5f 03 00 00 64 03 00 00 68 03 00 00 6d 03 00 00 72 03 00 00 76 03 00 00 7b 03 00 00 7f 03 00 00 84 03 00 00 88 03 00 00 8c 03 00 00 91 03 00 00 95 03 00 00 99 03 00 00 9e 03 00 00 a2 03 00 00 a6 03 00 00 ab 03 00 00 af 03 00 00 b3 03 00 00 b7 03 00 00 bb 03 00 00 bf 03 00 00 c4 03 00 00 c8 03 00 00 cc 03 00 00 d0 03 00 00 d4 03 00 00 d8 03 00 00 dc 03 00 00 e0 03 00 00 e4 03 00 00 e8 03 00 00 eb 03 00 00 ef 03 00 00 f3 03 00 00 f7 03 00 00 fb 03 00 00 ff 03 00 00];
		};
		iq_ccm {
			size = [40 02 00 00];
			data = [00 00 00 00 81 01 bc ff c4 ff aa ff c4 01 93 ff 03 00 6d ff 8f 01 80 80 80 80 80 80 80 80 80 80 80 80 80 80 80 80 80 80 80 80 80 80 80 80 00 00 00 00 00 00 00 00 00 00 00 00 00 00 00 00 00 00 00 00 00 00 00 00 00 00 00 00 00 00 00 00 00 00 00 00 00 00 00 00 00 00 00 00 00 00 00 00 00 00 00 00 00 00 00 00 00 00 00 00 00 00 00 00 00 00 00 00 00 00 00 00 00 00 00 00 00 00 00 00 00 00 00 00 00 00 00 00 00 00 00 00 00 00 00 00 00 00 64 19 00 00 81 01 bc ff c4 ff aa ff c4 01 93 ff 03 00 6d ff 8f 01 80 80 80 80 80 80 80 80 80 80 80 80 80 80 80 80 80 80 80 80 80 80 80 80 00 00 00 00 00 00 00 00 00 00 00 00 00 00 00 00 00 00 00 00 00 00 00 00 00 00 00 00 00 00 00 00 00 00 00 00 00 00 00 00 00 00 00 00 00 00 00 00 00 00 00 00 00 00 00 00 00 00 00 00 00 00 00 00 00 00 00 00 00 00 00 00 00 00 00 00 00 00 00 00 00 00 00 00 00 00 00 00 00 00 00 00 00 00 00 00 00 00 74 0e 00 00 58 01 cf ff da ff 89 ff b7 01 c0 ff fd ff 6f ff 94 01 80 80 80 80 80 80 80 80 80 80 80 80 80 80 80 80 80 80 80 80 80 80 80 80 00 00 00 00 00 00 00 00 00 00 00 00 00 00 00 00 00 00 00 00 00 00 00 00 00 00 00 00 00 00 00 00 00 00 00 00 00 00 00 00 00 00 00 00 00 00 00 00 00 00 00 00 00 00 00 00 00 00 00 00 00 00 00 00 00 00 00 00 00 00 00 00 00 00 00 00 00 00 00 00 00 00 00 00 00 00 00 00 00 00 00 00 00 00 00 00 00 00 f0 0a 00 00 f2 00 53 00 bb ff 6a ff be 01 d8 ff fd ff 29 ff db 01 80 80 80 80 80 80 80 80 80 80 80 80 80 80 80 80 80 80 80 80 80 80 80 80 00 00 00 00 00 00 00 00 00 00 00 00 00 00 00 00 00 00 00 00 00 00 00 00 00 00 00 00 00 00 00 00 00 00 00 00 00 00 00 00 00 00 00 00 00 00 00 00 00 00 00 00 00 00 00 00 00 00 00 00 00 00 00 00 00 00 00 00 00 00 00 00 00 00 00 00 00 00 00 00 00 00 00 00 00 00 00 00 00 00 00 00 00 00 00 00 00 00];
		};
		iq_color {
			size = [ec 06 00 00];
			data = [00 00 00 00 80 80 40 10 00 00 00 00 00 00 00 00 00 00 00 00 00 14 0f 0a 05 00 00 00 00 00 00 00 00 00 05 0a 0f 00 00 00 80 00 00 00 80 00 00 00 80 00 00 00 80 00 00 00 80 00 00 00 80 00 00 00 80 00 00 00 80 00 00 00 80 00 00 00 80 00 00 00 80 00 00 00 80 00 00 00 80 00 00 00 80 00 00 00 80 00 00 00 80 00 00 00 80 00 00 00 8c 80 40 10 00 00 00 00 00 00 00 00 00 00 00 00 00 14 0f 0a 05 00 00 00 00 00 00 00 00 00 05 0a 0f 00 00 00 80 00 00 00 80 00 00 00 80 00 00 00 80 00 00 00 80 00 00 00 80 00 00 00 80 00 00 00 80 00 00 00 80 00 00 00 80 00 00 00 80 00 00 00 80 00 00 00 80 00 00 00 80 00 00 00 80 00 00 00 80 00 00 00 80 00 00 00 8c 80 40 10 00 00 00 00 00 00 00 00 00 00 00 00 00 14 0f 0a 05 00 00 00 00 00 00 00 00 00 05 0a 0f 00 00 00 80 00 00 00 80 00 00 00 80 00 00 00 80 00 00 00 80 00 00 00 80 00 00 00 80 00 00 00 80 00 00 00 80 00 00 00 80 00 00 00 80 00 00 00 80 00 00 00 80 00 00 00 80 00 00 00 80 00 00 00 80 00 00 00 80 00 00 00 8c 80 40 10 00 00 00 00 00 00 00 00 00 00 00 00 00 14 0f 0a 05 00 00 00 00 00 00 00 00 00 05 0a 0f 00 00 00 80 00 00 00 80 00 00 00 80 00 00 00 80 00 00 00 80 00 00 00 80 00 00 00 80 00 00 00 80 00 00 00 80 00 00 00 80 00 00 00 80 00 00 00 80 00 00 00 80 00 00 00 80 00 00 00 80 00 00 00 80 00 00 00 80 00 00 00 87 80 40 10 00 00 00 00 00 00 00 00 00 00 00 00 00 14 0f 0a 05 00 00 00 00 00 00 00 00 00 05 0a 0f 00 00 00 80 00 00 00 80 00 00 00 80 00 00 00 80 00 00 00 80 00 00 00 80 00 00 00 80 00 00 00 80 00 00 00 80 00 00 00 80 00 00 00 80 00 00 00 80 00 00 00 80 00 00 00 80 00 00 00 80 00 00 00 80 00 00 00 80 00 00 00 87 80 40 10 00 00 00 00 00 00 00 00 00 00 00 00 00 14 0f 0a 05 00 00 00 00 00 00 00 00 00 05 0a 0f 00 00 00 80 00 00 00 80 00 00 00 80 00 00 00 80 00 00 00 80 00 00 00 80 00 00 00 80 00 00 00 80 00 00 00 80 00 00 00 80 00 00 00 80 00 00 00 80 00 00 00 80 00 00 00 80 00 00 00 80 00 00 00 80 00 00 00 80 00 00 00 82 80 40 10 00 00 00 00 00 00 00 00 00 00 00 00 00 14 0f 0a 05 00 00 00 00 00 00 00 00 00 05 0a 0f 00 00 00 80 00 00 00 80 00 00 00 80 00 00 00 80 00 00 00 80 00 00 00 80 00 00 00 80 00 00 00 80 00 00 00 80 00 00 00 80 00 00 00 80 00 00 00 80 00 00 00 80 00 00 00 80 00 00 00 80 00 00 00 80 00 00 00 80 00 00 00 82 80 40 10 00 00 00 00 00 00 00 00 00 00 00 00 00 14 0f 0a 05 00 00 00 00 00 00 00 00 00 05 14 28 00 00 00 80 00 00 00 80 00 00 00 80 00 00 00 80 00 00 00 80 00 00 00 80 00 00 00 80 00 00 00 80 00 00 00 80 00 00 00 80 00 00 00 80 00 00 00 80 00 00 00 80 00 00 00 80 00 00 00 80 00 00 00 80 00 00 00 80 00 00 00 80 80 40 10 00 00 00 00 00 00 00 00 00 00 00 00 00 14 0f 0a 05 00 00 00 00 00 00 00 00 00 05 14 28 00 00 00 80 00 00 00 80 00 00 00 80 00 00 00 80 00 00 00 80 00 00 00 80 00 00 00 80 00 00 00 80 00 00 00 80 00 00 00 80 00 00 00 80 00 00 00 80 00 00 00 80 00 00 00 80 00 00 00 80 00 00 00 80 00 00 00 80 00 00 00 80 80 40 10 00 00 00 00 00 00 00 00 00 00 00 00 00 14 0f 0a 05 00 00 00 00 00 00 00 00 00 05 14 28 00 00 00 80 00 00 00 80 00 00 00 80 00 00 00 80 00 00 00 80 00 00 00 80 00 00 00 80 00 00 00 80 00 00 00 80 00 00 00 80 00 00 00 80 00 00 00 80 00 00 00 80 00 00 00 80 00 00 00 80 00 00 00 80 00 00 00 80 00 00 00 80 80 40 10 00 00 00 00 00 00 00 00 00 00 00 00 00 14 0f 0a 05 00 00 00 00 00 00 00 00 00 05 14 28 00 00 00 80 00 00 00 80 00 00 00 80 00 00 00 80 00 00 00 80 00 00 00 80 00 00 00 80 00 00 00 80 00 00 00 80 00 00 00 80 00 00 00 80 00 00 00 80 00 00 00 80 00 00 00 80 00 00 00 80 00 00 00 80 00 00 00 80 00 00 00 80 80 40 10 00 00 00 00 00 00 00 00 00 00 00 00 00 14 0f 0a 05 00 00 00 00 00 00 00 00 00 05 1e 3c 00 00 00 80 00 00 00 80 00 00 00 80 00 00 00 80 00 00 00 80 00 00 00 80 00 00 00 80 00 00 00 80 00 00 00 80 00 00 00 80 00 00 00 80 00 00 00 80 00 00 00 80 00 00 00 80 00 00 00 80 00 00 00 80 00 00 00 80 00 00 00 80 80 40 10 00 00 00 00 00 00 00 00 00 00 00 00 00 14 0f 0a 05 00 00 00 00 00 00 00 00 00 05 1e 3c 00 00 00 80 00 00 00 80 00 00 00 80 00 00 00 80 00 00 00 80 00 00 00 80 00 00 00 80 00 00 00 80 00 00 00 80 00 00 00 80 00 00 00 80 00 00 00 80 00 00 00 80 00 00 00 80 00 00 00 80 00 00 00 80 00 00 00 80 00 00 00 80 80 40 10 00 00 00 00 00 00 00 00 00 00 00 00 00 14 0f 0a 05 00 00 00 00 00 00 00 00 00 05 0a 0f 00 00 00 80 00 00 00 80 00 00 00 80 00 00 00 80 00 00 00 80 00 00 00 80 00 00 00 80 00 00 00 80 00 00 00 80 00 00 00 80 00 00 00 80 00 00 00 80 00 00 00 80 00 00 00 80 00 00 00 80 00 00 00 80 00 00 00 80 00 00 00 80 80 40 10 00 00 00 00 00 00 00 00 00 00 00 00 00 14 0f 0a 05 00 00 00 00 00 00 00 00 00 05 0a 0f 00 00 00 80 00 00 00 80 00 00 00 80 00 00 00 80 00 00 00 80 00 00 00 80 00 00 00 80 00 00 00 80 00 00 00 80 00 00 00 80 00 00 00 80 00 00 00 80 00 00 00 80 00 00 00 80 00 00 00 80 00 00 00 80 00 00 00 80 00 00 00 80 80 40 10 00 00 00 00 00 00 00 00 00 00 00 00 00 14 0f 0a 05 00 00 00 00 00 00 00 00 00 05 0a 0f 00 00 00 80 00 00 00 80 00 00 00 80 00 00 00 80 00 00 00 80 00 00 00 80 00 00 00 80 00 00 00 80 00 00 00 80 00 00 00 80 00 00 00 80 00 00 00 80 00 00 00 80 00 00 00 80 00 00 00 80 00 00 00 80 00 00 00 80 00 00 00 80 80 40 10 00 00 00 00 00 00 00 00 00 00 00 00 00 14 0f 0a 05 00 00 00 00 00 00 00 00 00 05 0a 0f 00 00 00 80 00 00 00 80 00 00 00 80 00 00 00 80 00 00 00 80 00 00 00 80 00 00 00 80 00 00 00 80 00 00 00 80 00 00 00 80 00 00 00 80 00 00 00 80 00 00 00 80 00 00 00 80 00 00 00 80 00 00 00 80 00 00 00 80 00 00 00];
		};
		iq_contrast {
			size = [b0 00 00 00];
			data = [00 00 00 00 80 00 00 00 00 00 00 00 00 00 8c 14 14 14 14 14 14 14 14 14 8c 14 14 14 14 14 14 14 14 14 8c 14 14 14 14 14 14 14 14 14 87 14 14 14 14 14 14 14 14 14 84 14 14 14 14 14 14 14 14 14 84 14 14 14 14 14 14 14 14 14 84 0a 0a 0a 0a 0a 0a 0a 0a 0a 84 0a 0a 0a 0a 0a 0a 0a 0a 0a 87 0a 0a 0a 0a 0a 0a 0a 0a 0a 87 0a 0a 0a 0a 0a 0a 0a 0a 0a 84 0a 0a 0a 0a 0a 0a 0a 0a 0a 84 0a 0a 0a 0a 0a 0a 0a 0a 0a 80 0a 0a 0a 0a 0a 0a 0a 0a 0a 80 0a 0a 0a 0a 0a 0a 0a 0a 0a 80 0a 0a 0a 0a 0a 0a 0a 0a 0a 80 0a 0a 0a 0a 0a 0a 0a 0a 0a 00 00];
		};
		iq_edge {
			size = [e0 05 00 00];
			data = [01 00 00 00 00 00 00 00 b4 00 00 00 14 00 00 00 00 10 20 40 80 b4 f0 ff ff f0 e2 d6 cc c4 be b8 20 2d 35 40 40 40 40 40 40 40 40 40 40 34 2c 26 80 80 80 80 80 80 80 80 80 80 80 80 80 80 80 80 80 80 80 80 80 80 80 80 40 00 00 00 80 00 00 00 80 00 00 00 08 00 00 00 00 00 00 00 00 00 00 00 10 00 00 00 08 00 00 00 28 00 00 00 f0 00 00 00 00 01 00 00 40 50 00 00 00 01 00 00 00 01 00 00 00 00 00 00 80 00 00 00 00 00 00 00 02 00 00 00 00 00 00 00 00 02 00 00 00 00 00 00 05 00 00 00 3c 00 00 00 3c 00 00 00 10 00 00 00 10 00 00 00 00 00 00 00 10 00 00 00 1c 00 00 00 3c 00 00 00 64 00 00 00 74 00 00 00 40 50 00 00 00 01 00 00 00 01 00 00 00 00 00 00 50 00 00 00 00 00 00 00 05 00 00 00 00 00 00 00 00 02 00 00 00 00 00 00 05 00 00 00 3c 00 00 00 3c 00 00 00 10 00 00 00 10 00 00 00 00 00 00 00 10 00 00 00 21 00 00 00 41 00 00 00 6e 00 00 00 7e 00 00 00 40 50 00 00 00 01 00 00 00 01 00 00 00 00 00 00 50 00 00 00 00 00 00 00 05 00 00 00 00 00 00 00 00 02 00 00 00 00 00 00 05 00 00 00 3c 00 00 00 3c 00 00 00 10 00 00 00 10 00 00 00 00 00 00 00 10 00 00 00 26 00 00 00 46 00 00 00 78 00 00 00 88 00 00 00 40 50 00 00 00 01 00 00 00 01 00 00 00 00 00 00 50 00 00 00 00 00 00 00 05 00 00 00 00 00 00 00 00 02 00 00 00 00 00 00 05 00 00 00 3c 00 00 00 3c 00 00 00 0c 00 00 00 0c 00 00 00 00 00 00 00 10 00 00 00 2a 00 00 00 4b 00 00 00 82 00 00 00 92 00 00 00 40 50 00 00 00 01 00 00 00 01 00 00 00 00 00 00 50 00 00 00 00 00 00 00 05 00 00 00 00 00 00 00 00 02 00 00 00 00 00 00 05 00 00 00 3c 00 00 00 3c 00 00 00 0c 00 00 00 0c 00 00 00 00 00 00 00 10 00 00 00 3a 00 00 00 5a 00 00 00 96 00 00 00 a6 00 00 00 40 50 00 00 00 01 00 00 00 01 00 00 00 00 00 00 50 00 00 00 00 00 00 00 05 00 00 00 00 00 00 00 00 02 00 00 00 00 00 00 05 00 00 00 3c 00 00 00 3c 00 00 00 0c 00 00 00 0c 00 00 00 00 00 00 00 10 00 00 00 62 00 00 00 82 00 00 00 be 00 00 00 ce 00 00 00 40 50 00 00 00 01 00 00 00 01 00 00 00 00 00 00 50 00 00 00 00 00 00 00 05 00 00 00 00 00 00 00 00 02 00 00 00 00 00 00 05 00 00 00 3c 00 00 00 3c 00 00 00 08 00 00 00 08 00 00 00 00 00 00 00 10 00 00 00 6c 00 00 00 8c 00 00 00 dc 00 00 00 ec 00 00 00 40 50 00 00 00 01 00 00 00 01 00 00 00 00 00 00 50 00 00 00 02 00 00 00 05 00 00 00 00 00 00 00 00 02 00 00 02 00 00 00 04 00 00 00 3c 00 00 00 3c 00 00 00 08 00 00 00 08 00 00 00 00 00 00 00 10 00 00 00 94 00 00 00 b4 00 00 00 04 01 00 00 14 01 00 00 40 50 00 00 00 01 00 00 00 01 00 00 00 00 00 00 50 00 00 00 02 00 00 00 05 00 00 00 00 00 00 00 00 02 00 00 02 00 00 00 04 00 00 00 5a 00 00 00 5a 00 00 00 08 00 00 00 08 00 00 00 00 00 00 00 10 00 00 00 d0 00 00 00 f0 00 00 00 40 01 00 00 50 01 00 00 40 50 00 00 00 01 00 00 00 01 00 00 00 00 00 00 50 00 00 00 01 00 00 00 05 00 00 00 00 00 00 00 00 02 00 00 02 00 00 00 04 00 00 00 64 00 00 00 64 00 00 00 02 00 00 00 02 00 00 00 00 00 00 00 10 00 00 00 bc 00 00 00 dc 00 00 00 2c 01 00 00 3c 01 00 00 40 50 00 00 00 01 00 00 00 01 00 00 00 00 00 00 50 00 00 00 00 00 00 00 05 00 00 00 00 00 00 00 00 02 00 00 02 00 00 00 04 00 00 00 64 00 00 00 64 00 00 00 02 00 00 00 02 00 00 00 00 00 00 00 10 00 00 00 0c 01 00 00 2c 01 00 00 90 01 00 00 a0 01 00 00 40 50 00 00 00 01 00 00 00 01 00 00 00 00 00 00 50 00 00 00 00 00 00 00 05 00 00 00 00 00 00 00 00 02 00 00 02 00 00 00 04 00 00 00 64 00 00 00 64 00 00 00 00 00 00 00 00 00 00 00 00 00 00 00 10 00 00 00 34 01 00 00 54 01 00 00 a4 01 00 00 b4 01 00 00 40 50 00 00 00 01 00 00 00 01 00 00 00 00 00 00 50 00 00 00 00 00 00 00 05 00 00 00 00 00 00 00 00 02 00 00 02 00 00 00 04 00 00 00 3c 00 00 00 3c 00 00 00 00 00 00 00 00 00 00 00 00 00 00 00 04 00 00 00 73 02 00 00 93 02 00 00 f5 02 00 00 08 03 00 00 40 50 00 00 00 01 00 00 00 01 00 00 00 00 00 00 80 00 00 00 05 00 00 00 02 00 00 00 00 00 00 00 00 02 00 00 00 00 00 00 05 00 00 00 3c 00 00 00 3c 00 00 00 00 00 00 00 00 00 00 00 00 00 00 00 04 00 00 00 73 02 00 00 93 02 00 00 f5 02 00 00 08 03 00 00 40 50 00 00 00 01 00 00 00 01 00 00 00 00 00 00 80 00 00 00 05 00 00 00 02 00 00 00 00 00 00 00 00 02 00 00 00 00 00 00 05 00 00 00 3c 00 00 00 3c 00 00 00 00 00 00 00 00 00 00 00 00 00 00 00 04 00 00 00 73 02 00 00 93 02 00 00 f5 02 00 00 08 03 00 00 40 50 00 00 00 01 00 00 00 01 00 00 00 00 00 00 80 00 00 00 05 00 00 00 02 00 00 00 00 00 00 00 00 02 00 00 00 00 00 00 05 00 00 00 3c 00 00 00 3c 00 00 00 00 00 00 00 00 00 00 00 00 00 00 00 04 00 00 00 73 02 00 00 93 02 00 00 f5 02 00 00 08 03 00 00 40 50 00 00 00 01 00 00 00 01 00 00 00 00 00 00 80 00 00 00 05 00 00 00 02 00 00 00 00 00 00 00 00 02 00 00 00 00 00 00 05 00 00 00];
		};
		iq_3dnr {
			size = [64 1f 00 00];
			data = [01 00 00 00 00 00 00 00 00 00 00 00 00 00 00 00 0f 00 00 00 40 00 00 00 40 00 00 00 00 00 00 00 80 00 00 00 80 00 00 00 80 00 00 00 c8 00 00 00 c8 00 00 00 04 00 00 00 04 00 00 00 03 00 00 00 04 00 00 00 04 00 00 00 04 00 00 00 04 00 00 00 04 00 00 00 05 00 00 00 05 00 00 00 06 00 00 00 06 00 00 00 07 00 00 00 07 00 00 00 08 00 00 00 08 00 00 00 80 00 00 00 04 00 00 00 00 00 00 00 00 00 00 00 00 00 00 00 00 00 00 00 00 00 00 00 00 00 00 00 00 00 00 00 00 00 00 00 00 00 00 00 00 00 00 00 00 00 00 00 00 00 00 00 00 00 00 00 00 00 00 00 00 00 00 00 00 00 00 00 00 00 00 00 00 00 00 00 00 00 00 00 00 00 00 00 00 00 00 00 00 00 00 00 00 00 00 00 00 00 00 00 00 00 00 00 00 00 00 00 00 00 00 00 00 00 00 00 00 00 00 00 00 00 00 00 00 00 00 00 00 00 00 00 08 00 00 00 10 00 00 00 04 00 00 00 10 00 00 00 20 00 00 00 06 00 00 00 01 01 01 00 01 00 00 00 00 00 00 00 00 00 00 00 00 00 00 00 10 00 00 00 20 00 00 00 30 00 00 00 40 00 00 00 80 00 00 00 40 00 00 00 00 01 00 00 00 01 00 00 10 00 00 00 10 00 00 00 10 00 00 00 10 00 00 00 10 00 00 00 10 00 00 00 10 00 00 00 10 00 00 00 10 00 00 00 10 00 00 00 10 00 00 00 10 00 00 00 08 00 00 00 10 00 00 00 40 00 00 00 40 00 00 00 10 00 00 00 08 00 00 00 00 00 00 00 06 00 00 00 0c 00 00 00 18 00 00 00 28 00 00 00 4c 00 00 00 60 00 00 00 70 00 00 00 80 00 00 00 40 00 00 00 00 00 00 00 06 00 00 00 0c 00 00 00 18 00 00 00 28 00 00 00 4c 00 00 00 60 00 00 00 70 00 00 00 80 00 00 00 40 00 00 00 04 01 00 00 00 00 00 00 0f 00 00 00 20 00 00 00 20 00 00 00 00 00 00 00 40 00 00 00 40 00 00 00 40 00 00 00 50 00 00 00 50 00 00 00 04 00 00 00 04 00 00 00 03 00 00 00 04 00 00 00 04 00 00 00 04 00 00 00 04 00 00 00 04 00 00 00 1a 00 00 00 1a 00 00 00 1a 00 00 00 1a 00 00 00 1a 00 00 00 1b 00 00 00 1b 00 00 00 1c 00 00 00 dc 00 00 00 06 00 00 00 28 00 00 00 28 00 00 00 28 00 00 00 28 00 00 00 28 00 00 00 3c 00 00 00 3c 00 00 00 3c 00 00 00 07 00 00 00 07 00 00 00 07 00 00 00 07 00 00 00 06 00 00 00 06 00 00 00 06 00 00 00 06 00 00 00 19 00 00 00 19 00 00 00 19 00 00 00 19 00 00 00 14 00 00 00 14 00 00 00 14 00 00 00 14 00 00 00 14 00 00 00 19 00 00 00 19 00 00 00 19 00 00 00 14 00 00 00 14 00 00 00 14 00 00 00 14 00 00 00 08 00 00 00 10 00 00 00 03 00 00 00 10 00 00 00 20 00 00 00 03 00 00 00 01 01 01 00 01 00 00 00 00 00 00 00 00 00 00 00 00 00 00 00 04 00 00 00 06 00 00 00 08 00 00 00 0a 00 00 00 80 00 00 00 40 00 00 00 fa 00 00 00 fa 00 00 00 10 00 00 00 14 00 00 00 18 00 00 00 1c 00 00 00 10 00 00 00 10 00 00 00 10 00 00 00 10 00 00 00 10 00 00 00 10 00 00 00 10 00 00 00 10 00 00 00 00 00 00 00 00 00 00 00 00 00 00 00 40 00 00 00 20 00 00 00 00 00 00 00 00 00 00 00 10 00 00 00 20 00 00 00 30 00 00 00 40 00 00 00 50 00 00 00 60 00 00 00 70 00 00 00 80 00 00 00 40 00 00 00 00 00 00 00 0b 00 00 00 15 00 00 00 1e 00 00 00 28 00 00 00 37 00 00 00 4b 00 00 00 60 00 00 00 80 00 00 00 40 00 00 00 04 01 00 00 00 00 00 00 00 00 00 00 28 00 00 00 28 00 00 00 00 00 00 00 48 00 00 00 48 00 00 00 48 00 00 00 60 00 00 00 60 00 00 00 04 00 00 00 04 00 00 00 03 00 00 00 04 00 00 00 04 00 00 00 04 00 00 00 04 00 00 00 04 00 00 00 1a 00 00 00 1a 00 00 00 1a 00 00 00 1a 00 00 00 1a 00 00 00 1b 00 00 00 1b 00 00 00 1c 00 00 00 dc 00 00 00 06 00 00 00 28 00 00 00 28 00 00 00 28 00 00 00 28 00 00 00 28 00 00 00 3c 00 00 00 3c 00 00 00 3c 00 00 00 09 00 00 00 09 00 00 00 09 00 00 00 09 00 00 00 08 00 00 00 08 00 00 00 08 00 00 00 08 00 00 00 23 00 00 00 23 00 00 00 23 00 00 00 23 00 00 00 1e 00 00 00 1e 00 00 00 1e 00 00 00 1e 00 00 00 14 00 00 00 19 00 00 00 19 00 00 00 19 00 00 00 14 00 00 00 14 00 00 00 14 00 00 00 14 00 00 00 08 00 00 00 10 00 00 00 03 00 00 00 10 00 00 00 20 00 00 00 03 00 00 00 01 01 01 00 01 00 00 00 00 00 00 00 00 00 00 00 00 00 00 00 04 00 00 00 06 00 00 00 08 00 00 00 0a 00 00 00 80 00 00 00 40 00 00 00 fa 00 00 00 fa 00 00 00 10 00 00 00 14 00 00 00 18 00 00 00 1c 00 00 00 10 00 00 00 10 00 00 00 10 00 00 00 10 00 00 00 10 00 00 00 10 00 00 00 10 00 00 00 10 00 00 00 00 00 00 00 00 00 00 00 00 00 00 00 40 00 00 00 20 00 00 00 00 00 00 00 00 00 00 00 10 00 00 00 20 00 00 00 30 00 00 00 40 00 00 00 50 00 00 00 60 00 00 00 70 00 00 00 80 00 00 00 40 00 00 00 00 00 00 00 0b 00 00 00 15 00 00 00 1e 00 00 00 28 00 00 00 37 00 00 00 4b 00 00 00 60 00 00 00 80 00 00 00 40 00 00 00 00 00 00 00 00 00 00 00 00 00 00 00 30 00 00 00 30 00 00 00 00 00 00 00 50 00 00 00 50 00 00 00 50 00 00 00 70 00 00 00 70 00 00 00 04 00 00 00 04 00 00 00 03 00 00 00 04 00 00 00 04 00 00 00 04 00 00 00 04 00 00 00 04 00 00 00 1a 00 00 00 1a 00 00 00 1a 00 00 00 1a 00 00 00 1a 00 00 00 1b 00 00 00 1b 00 00 00 1c 00 00 00 dc 00 00 00 06 00 00 00 28 00 00 00 28 00 00 00 28 00 00 00 28 00 00 00 28 00 00 00 3c 00 00 00 3c 00 00 00 3c 00 00 00 0c 00 00 00 0c 00 00 00 0c 00 00 00 0c 00 00 00 0b 00 00 00 0b 00 00 00 0b 00 00 00 0b 00 00 00 37 00 00 00 37 00 00 00 37 00 00 00 37 00 00 00 32 00 00 00 32 00 00 00 32 00 00 00 32 00 00 00 14 00 00 00 19 00 00 00 19 00 00 00 19 00 00 00 14 00 00 00 14 00 00 00 14 00 00 00 14 00 00 00 08 00 00 00 10 00 00 00 03 00 00 00 10 00 00 00 20 00 00 00 03 00 00 00 01 01 01 00 01 00 00 00 00 00 00 00 00 00 00 00 00 00 00 00 04 00 00 00 06 00 00 00 08 00 00 00 0a 00 00 00 80 00 00 00 40 00 00 00 fa 00 00 00 f4 01 00 00 10 00 00 00 14 00 00 00 18 00 00 00 1c 00 00 00 10 00 00 00 10 00 00 00 10 00 00 00 10 00 00 00 10 00 00 00 10 00 00 00 10 00 00 00 10 00 00 00 00 00 00 00 08 00 00 00 20 00 00 00 40 00 00 00 20 00 00 00 00 00 00 00 00 00 00 00 10 00 00 00 20 00 00 00 30 00 00 00 40 00 00 00 50 00 00 00 60 00 00 00 70 00 00 00 80 00 00 00 40 00 00 00 00 00 00 00 0b 00 00 00 15 00 00 00 1e 00 00 00 28 00 00 00 37 00 00 00 4b 00 00 00 60 00 00 00 80 00 00 00 40 00 00 00 00 00 00 00 00 00 00 00 00 00 00 00 50 00 00 00 50 00 00 00 00 00 00 00 70 00 00 00 70 00 00 00 70 00 00 00 90 00 00 00 90 00 00 00 04 00 00 00 04 00 00 00 03 00 00 00 04 00 00 00 04 00 00 00 04 00 00 00 04 00 00 00 04 00 00 00 1a 00 00 00 1a 00 00 00 1a 00 00 00 1a 00 00 00 1a 00 00 00 1b 00 00 00 1b 00 00 00 1c 00 00 00 dc 00 00 00 06 00 00 00 28 00 00 00 28 00 00 00 28 00 00 00 28 00 00 00 28 00 00 00 3c 00 00 00 3c 00 00 00 3c 00 00 00 0e 00 00 00 0e 00 00 00 0e 00 00 00 0e 00 00 00 0e 00 00 00 0d 00 00 00 0d 00 00 00 0d 00 00 00 4b 00 00 00 4b 00 00 00 4b 00 00 00 4b 00 00 00 4b 00 00 00 46 00 00 00 46 00 00 00 46 00 00 00 19 00 00 00 1e 00 00 00 1e 00 00 00 1e 00 00 00 19 00 00 00 19 00 00 00 19 00 00 00 19 00 00 00 08 00 00 00 10 00 00 00 03 00 00 00 10 00 00 00 20 00 00 00 03 00 00 00 01 01 01 00 01 00 00 00 00 00 00 00 00 00 00 00 00 00 00 00 06 00 00 00 08 00 00 00 0a 00 00 00 0c 00 00 00 80 00 00 00 40 00 00 00 fa 00 00 00 f4 01 00 00 10 00 00 00 14 00 00 00 18 00 00 00 1c 00 00 00 10 00 00 00 10 00 00 00 10 00 00 00 10 00 00 00 10 00 00 00 10 00 00 00 10 00 00 00 10 00 00 00 00 00 00 00 10 00 00 00 40 00 00 00 80 00 00 00 40 00 00 00 08 00 00 00 00 00 00 00 0b 00 00 00 15 00 00 00 1e 00 00 00 28 00 00 00 37 00 00 00 4b 00 00 00 60 00 00 00 80 00 00 00 40 00 00 00 00 00 00 00 0b 00 00 00 15 00 00 00 1e 00 00 00 28 00 00 00 37 00 00 00 4b 00 00 00 60 00 00 00 80 00 00 00 40 00 00 00 00 00 00 00 00 00 00 00 00 00 00 00 60 00 00 00 60 00 00 00 00 00 00 00 90 00 00 00 90 00 00 00 90 00 00 00 c0 00 00 00 c0 00 00 00 04 00 00 00 04 00 00 00 03 00 00 00 04 00 00 00 04 00 00 00 04 00 00 00 04 00 00 00 04 00 00 00 1a 00 00 00 1a 00 00 00 1a 00 00 00 1a 00 00 00 1a 00 00 00 1b 00 00 00 1b 00 00 00 1c 00 00 00 dc 00 00 00 06 00 00 00 28 00 00 00 28 00 00 00 28 00 00 00 28 00 00 00 28 00 00 00 3c 00 00 00 3c 00 00 00 3c 00 00 00 10 00 00 00 10 00 00 00 10 00 00 00 10 00 00 00 10 00 00 00 0f 00 00 00 0f 00 00 00 0f 00 00 00 55 00 00 00 55 00 00 00 55 00 00 00 55 00 00 00 55 00 00 00 50 00 00 00 50 00 00 00 50 00 00 00 19 00 00 00 1e 00 00 00 1e 00 00 00 1e 00 00 00 19 00 00 00 19 00 00 00 19 00 00 00 19 00 00 00 08 00 00 00 10 00 00 00 03 00 00 00 10 00 00 00 20 00 00 00 03 00 00 00 01 01 01 00 01 00 00 00 00 00 00 00 00 00 00 00 00 00 00 00 06 00 00 00 08 00 00 00 0a 00 00 00 0c 00 00 00 80 00 00 00 40 00 00 00 fa 00 00 00 f4 01 00 00 10 00 00 00 14 00 00 00 18 00 00 00 1c 00 00 00 10 00 00 00 10 00 00 00 10 00 00 00 10 00 00 00 10 00 00 00 10 00 00 00 10 00 00 00 10 00 00 00 00 00 00 00 10 00 00 00 40 00 00 00 80 00 00 00 40 00 00 00 08 00 00 00 00 00 00 00 07 00 00 00 0e 00 00 00 18 00 00 00 20 00 00 00 30 00 00 00 46 00 00 00 60 00 00 00 80 00 00 00 40 00 00 00 00 00 00 00 0b 00 00 00 15 00 00 00 1e 00 00 00 28 00 00 00 37 00 00 00 4b 00 00 00 60 00 00 00 80 00 00 00 40 00 00 00 00 00 00 00 00 00 00 00 00 00 00 00 60 00 00 00 60 00 00 00 00 00 00 00 a0 00 00 00 a0 00 00 00 a0 00 00 00 f0 00 00 00 f0 00 00 00 04 00 00 00 04 00 00 00 03 00 00 00 04 00 00 00 04 00 00 00 04 00 00 00 04 00 00 00 04 00 00 00 1a 00 00 00 1a 00 00 00 1a 00 00 00 1a 00 00 00 1a 00 00 00 1b 00 00 00 1b 00 00 00 1c 00 00 00 dc 00 00 00 06 00 00 00 28 00 00 00 28 00 00 00 28 00 00 00 28 00 00 00 28 00 00 00 3c 00 00 00 3c 00 00 00 3c 00 00 00 11 00 00 00 11 00 00 00 11 00 00 00 11 00 00 00 11 00 00 00 10 00 00 00 10 00 00 00 10 00 00 00 5f 00 00 00 5f 00 00 00 5f 00 00 00 5f 00 00 00 5f 00 00 00 5a 00 00 00 5a 00 00 00 5a 00 00 00 19 00 00 00 1e 00 00 00 1e 00 00 00 1e 00 00 00 19 00 00 00 19 00 00 00 19 00 00 00 19 00 00 00 08 00 00 00 10 00 00 00 03 00 00 00 10 00 00 00 20 00 00 00 03 00 00 00 01 01 01 00 01 00 00 00 00 00 00 00 00 00 00 00 00 00 00 00 0a 00 00 00 0c 00 00 00 0e 00 00 00 10 00 00 00 80 00 00 00 40 00 00 00 f4 01 00 00 bc 02 00 00 10 00 00 00 14 00 00 00 18 00 00 00 1c 00 00 00 10 00 00 00 10 00 00 00 10 00 00 00 10 00 00 00 10 00 00 00 10 00 00 00 10 00 00 00 10 00 00 00 00 00 00 00 10 00 00 00 40 00 00 00 ff 00 00 00 60 00 00 00 10 00 00 00 00 00 00 00 07 00 00 00 0e 00 00 00 18 00 00 00 20 00 00 00 30 00 00 00 46 00 00 00 60 00 00 00 80 00 00 00 40 00 00 00 00 00 00 00 0b 00 00 00 15 00 00 00 1e 00 00 00 28 00 00 00 37 00 00 00 4b 00 00 00 60 00 00 00 80 00 00 00 40 00 00 00 00 00 00 00 00 00 00 00 00 00 00 00 70 00 00 00 70 00 00 00 00 00 00 00 c0 00 00 00 c0 00 00 00 c0 00 00 00 18 01 00 00 18 01 00 00 04 00 00 00 04 00 00 00 03 00 00 00 04 00 00 00 04 00 00 00 04 00 00 00 04 00 00 00 04 00 00 00 1a 00 00 00 1a 00 00 00 1a 00 00 00 1a 00 00 00 1a 00 00 00 1b 00 00 00 1b 00 00 00 1c 00 00 00 dc 00 00 00 06 00 00 00 28 00 00 00 28 00 00 00 28 00 00 00 28 00 00 00 28 00 00 00 3c 00 00 00 3c 00 00 00 3c 00 00 00 13 00 00 00 13 00 00 00 13 00 00 00 13 00 00 00 13 00 00 00 12 00 00 00 12 00 00 00 12 00 00 00 69 00 00 00 69 00 00 00 69 00 00 00 69 00 00 00 69 00 00 00 64 00 00 00 64 00 00 00 64 00 00 00 19 00 00 00 1e 00 00 00 1e 00 00 00 1e 00 00 00 19 00 00 00 19 00 00 00 19 00 00 00 19 00 00 00 08 00 00 00 10 00 00 00 03 00 00 00 10 00 00 00 20 00 00 00 03 00 00 00 01 01 01 00 01 00 00 00 00 00 00 00 00 00 00 00 00 00 00 00 10 00 00 00 12 00 00 00 14 00 00 00 16 00 00 00 80 00 00 00 40 00 00 00 f4 01 00 00 20 03 00 00 10 00 00 00 14 00 00 00 18 00 00 00 1c 00 00 00 10 00 00 00 10 00 00 00 10 00 00 00 10 00 00 00 10 00 00 00 10 00 00 00 10 00 00 00 10 00 00 00 00 00 00 00 20 00 00 00 50 00 00 00 ff 00 00 00 60 00 00 00 10 00 00 00 00 00 00 00 07 00 00 00 0e 00 00 00 18 00 00 00 20 00 00 00 30 00 00 00 46 00 00 00 60 00 00 00 80 00 00 00 40 00 00 00 00 00 00 00 0b 00 00 00 15 00 00 00 1e 00 00 00 28 00 00 00 37 00 00 00 4b 00 00 00 60 00 00 00 80 00 00 00 40 00 00 00 00 00 00 00 00 00 00 00 00 00 00 00 80 00 00 00 80 00 00 00 00 00 00 00 e0 00 00 00 e0 00 00 00 e0 00 00 00 58 01 00 00 58 01 00 00 04 00 00 00 04 00 00 00 03 00 00 00 04 00 00 00 04 00 00 00 04 00 00 00 04 00 00 00 04 00 00 00 1a 00 00 00 1a 00 00 00 1a 00 00 00 1a 00 00 00 1a 00 00 00 1b 00 00 00 1b 00 00 00 1c 00 00 00 dc 00 00 00 06 00 00 00 28 00 00 00 28 00 00 00 28 00 00 00 28 00 00 00 28 00 00 00 3c 00 00 00 3c 00 00 00 3c 00 00 00 15 00 00 00 15 00 00 00 15 00 00 00 15 00 00 00 15 00 00 00 14 00 00 00 14 00 00 00 14 00 00 00 73 00 00 00 73 00 00 00 73 00 00 00 73 00 00 00 73 00 00 00 6e 00 00 00 6e 00 00 00 6e 00 00 00 19 00 00 00 1e 00 00 00 1e 00 00 00 1e 00 00 00 19 00 00 00 19 00 00 00 19 00 00 00 19 00 00 00 08 00 00 00 10 00 00 00 03 00 00 00 10 00 00 00 20 00 00 00 03 00 00 00 01 01 01 00 01 00 00 00 00 00 00 00 00 00 00 00 00 00 00 00 10 00 00 00 12 00 00 00 14 00 00 00 16 00 00 00 80 00 00 00 40 00 00 00 f4 01 00 00 e8 03 00 00 10 00 00 00 14 00 00 00 18 00 00 00 1c 00 00 00 10 00 00 00 10 00 00 00 10 00 00 00 10 00 00 00 10 00 00 00 10 00 00 00 10 00 00 00 10 00 00 00 00 00 00 00 20 00 00 00 50 00 00 00 ff 00 00 00 60 00 00 00 10 00 00 00 00 00 00 00 07 00 00 00 0e 00 00 00 18 00 00 00 20 00 00 00 30 00 00 00 46 00 00 00 60 00 00 00 00 00 00 00 00 00 00 00 00 00 00 00 0b 00 00 00 15 00 00 00 1e 00 00 00 28 00 00 00 37 00 00 00 4b 00 00 00 60 00 00 00 80 00 00 00 40 00 00 00 00 00 00 00 00 00 00 00 00 00 00 00 80 00 00 00 80 00 00 00 00 00 00 00 00 01 00 00 00 01 00 00 00 01 00 00 98 01 00 00 98 01 00 00 04 00 00 00 04 00 00 00 03 00 00 00 04 00 00 00 04 00 00 00 04 00 00 00 04 00 00 00 04 00 00 00 1a 00 00 00 1a 00 00 00 1a 00 00 00 1a 00 00 00 1a 00 00 00 1b 00 00 00 1b 00 00 00 1c 00 00 00 dc 00 00 00 06 00 00 00 28 00 00 00 28 00 00 00 28 00 00 00 28 00 00 00 28 00 00 00 3c 00 00 00 3c 00 00 00 3c 00 00 00 17 00 00 00 17 00 00 00 17 00 00 00 17 00 00 00 17 00 00 00 16 00 00 00 16 00 00 00 16 00 00 00 96 00 00 00 96 00 00 00 96 00 00 00 87 00 00 00 87 00 00 00 82 00 00 00 82 00 00 00 82 00 00 00 32 00 00 00 32 00 00 00 2d 00 00 00 28 00 00 00 23 00 00 00 23 00 00 00 23 00 00 00 23 00 00 00 08 00 00 00 10 00 00 00 03 00 00 00 10 00 00 00 20 00 00 00 03 00 00 00 01 01 01 00 01 00 00 00 00 00 00 00 00 00 00 00 00 00 00 00 20 00 00 00 24 00 00 00 28 00 00 00 2c 00 00 00 80 00 00 00 40 00 00 00 f4 01 00 00 e8 03 00 00 10 00 00 00 14 00 00 00 18 00 00 00 1c 00 00 00 10 00 00 00 10 00 00 00 10 00 00 00 10 00 00 00 10 00 00 00 10 00 00 00 10 00 00 00 10 00 00 00 00 00 00 00 20 00 00 00 50 00 00 00 ff 00 00 00 60 00 00 00 10 00 00 00 00 00 00 00 07 00 00 00 0e 00 00 00 18 00 00 00 20 00 00 00 30 00 00 00 46 00 00 00 60 00 00 00 80 00 00 00 40 00 00 00 00 00 00 00 0b 00 00 00 15 00 00 00 1e 00 00 00 28 00 00 00 37 00 00 00 4b 00 00 00 60 00 00 00 80 00 00 00 40 00 00 00 00 00 00 00 00 00 00 00 00 00 00 00 90 00 00 00 90 00 00 00 00 00 00 00 28 01 00 00 28 01 00 00 28 01 00 00 e0 01 00 00 e0 01 00 00 03 00 00 00 03 00 00 00 01 00 00 00 03 00 00 00 03 00 00 00 03 00 00 00 03 00 00 00 03 00 00 00 10 00 00 00 10 00 00 00 10 00 00 00 10 00 00 00 10 00 00 00 11 00 00 00 11 00 00 00 12 00 00 00 dc 00 00 00 06 00 00 00 28 00 00 00 28 00 00 00 28 00 00 00 28 00 00 00 28 00 00 00 3c 00 00 00 3c 00 00 00 3c 00 00 00 1d 00 00 00 1d 00 00 00 1d 00 00 00 1b 00 00 00 1b 00 00 00 1a 00 00 00 1a 00 00 00 1a 00 00 00 aa 00 00 00 aa 00 00 00 aa 00 00 00 9b 00 00 00 9b 00 00 00 96 00 00 00 96 00 00 00 96 00 00 00 46 00 00 00 46 00 00 00 41 00 00 00 3c 00 00 00 37 00 00 00 37 00 00 00 37 00 00 00 37 00 00 00 08 00 00 00 10 00 00 00 03 00 00 00 10 00 00 00 20 00 00 00 03 00 00 00 01 01 01 00 01 00 00 00 00 00 00 00 00 00 00 00 00 00 00 00 58 00 00 00 60 00 00 00 68 00 00 00 70 00 00 00 80 00 00 00 40 00 00 00 f4 01 00 00 e8 03 00 00 10 00 00 00 14 00 00 00 18 00 00 00 1c 00 00 00 10 00 00 00 10 00 00 00 10 00 00 00 10 00 00 00 10 00 00 00 10 00 00 00 10 00 00 00 10 00 00 00 00 00 00 00 60 00 00 00 ff 00 00 00 ff 00 00 00 60 00 00 00 10 00 00 00 00 00 00 00 07 00 00 00 0e 00 00 00 18 00 00 00 20 00 00 00 30 00 00 00 46 00 00 00 60 00 00 00 80 00 00 00 40 00 00 00 00 00 00 00 0b 00 00 00 15 00 00 00 1e 00 00 00 28 00 00 00 37 00 00 00 4b 00 00 00 60 00 00 00 80 00 00 00 40 00 00 00 00 00 00 00 00 00 00 00 00 00 00 00 c0 00 00 00 c0 00 00 00 00 00 00 00 28 01 00 00 28 01 00 00 28 01 00 00 80 02 00 00 80 02 00 00 03 00 00 00 03 00 00 00 01 00 00 00 03 00 00 00 03 00 00 00 03 00 00 00 03 00 00 00 03 00 00 00 10 00 00 00 10 00 00 00 10 00 00 00 10 00 00 00 10 00 00 00 11 00 00 00 11 00 00 00 12 00 00 00 dc 00 00 00 06 00 00 00 28 00 00 00 28 00 00 00 28 00 00 00 28 00 00 00 28 00 00 00 3c 00 00 00 3c 00 00 00 3c 00 00 00 22 00 00 00 22 00 00 00 22 00 00 00 1f 00 00 00 1f 00 00 00 1e 00 00 00 1e 00 00 00 1e 00 00 00 e1 00 00 00 e1 00 00 00 e1 00 00 00 cd 00 00 00 cd 00 00 00 c8 00 00 00 c8 00 00 00 c8 00 00 00 55 00 00 00 55 00 00 00 50 00 00 00 4b 00 00 00 46 00 00 00 46 00 00 00 46 00 00 00 46 00 00 00 08 00 00 00 10 00 00 00 03 00 00 00 10 00 00 00 20 00 00 00 03 00 00 00 01 01 01 00 01 00 00 00 00 00 00 00 00 00 00 00 00 00 00 00 80 00 00 00 88 00 00 00 90 00 00 00 98 00 00 00 80 00 00 00 40 00 00 00 ee 02 00 00 e8 03 00 00 10 00 00 00 14 00 00 00 18 00 00 00 1c 00 00 00 10 00 00 00 10 00 00 00 10 00 00 00 10 00 00 00 10 00 00 00 10 00 00 00 10 00 00 00 10 00 00 00 00 00 00 00 60 00 00 00 ff 00 00 00 ff 00 00 00 60 00 00 00 10 00 00 00 00 00 00 00 02 00 00 00 07 00 00 00 0c 00 00 00 16 00 00 00 23 00 00 00 34 00 00 00 4e 00 00 00 80 00 00 00 40 00 00 00 00 00 00 00 0b 00 00 00 15 00 00 00 1e 00 00 00 28 00 00 00 37 00 00 00 4b 00 00 00 60 00 00 00 80 00 00 00 40 00 00 00 00 00 00 00 00 00 00 00 00 00 00 00 e0 00 00 00 e0 00 00 00 00 00 00 00 38 01 00 00 38 01 00 00 38 01 00 00 00 03 00 00 00 03 00 00 03 00 00 00 03 00 00 00 01 00 00 00 03 00 00 00 03 00 00 00 03 00 00 00 03 00 00 00 03 00 00 00 10 00 00 00 10 00 00 00 10 00 00 00 10 00 00 00 10 00 00 00 11 00 00 00 11 00 00 00 12 00 00 00 dc 00 00 00 06 00 00 00 28 00 00 00 28 00 00 00 28 00 00 00 28 00 00 00 28 00 00 00 3c 00 00 00 3c 00 00 00 3c 00 00 00 25 00 00 00 25 00 00 00 25 00 00 00 22 00 00 00 22 00 00 00 21 00 00 00 21 00 00 00 21 00 00 00 09 01 00 00 09 01 00 00 09 01 00 00 f5 00 00 00 f5 00 00 00 f0 00 00 00 f0 00 00 00 f0 00 00 00 69 00 00 00 69 00 00 00 64 00 00 00 5f 00 00 00 5a 00 00 00 5a 00 00 00 5a 00 00 00 5a 00 00 00 08 00 00 00 10 00 00 00 03 00 00 00 10 00 00 00 20 00 00 00 03 00 00 00 01 01 01 00 01 00 00 00 00 00 00 00 00 00 00 00 00 00 00 00 98 00 00 00 a0 00 00 00 a8 00 00 00 b0 00 00 00 80 00 00 00 40 00 00 00 ee 02 00 00 e8 03 00 00 10 00 00 00 14 00 00 00 18 00 00 00 1c 00 00 00 10 00 00 00 10 00 00 00 10 00 00 00 10 00 00 00 10 00 00 00 10 00 00 00 10 00 00 00 10 00 00 00 00 00 00 00 60 00 00 00 ff 00 00 00 ff 00 00 00 60 00 00 00 10 00 00 00 00 00 00 00 00 00 00 00 00 00 00 00 06 00 00 00 0c 00 00 00 14 00 00 00 24 00 00 00 42 00 00 00 00 00 00 00 00 00 00 00 00 00 00 00 0b 00 00 00 15 00 00 00 1e 00 00 00 28 00 00 00 37 00 00 00 4b 00 00 00 60 00 00 00 80 00 00 00 40 00 00 00 00 00 00 00 00 00 00 00 00 00 00 00 2c 01 00 00 2c 01 00 00 00 00 00 00 58 02 00 00 58 02 00 00 58 02 00 00 20 03 00 00 20 03 00 00 03 00 00 00 03 00 00 00 03 00 00 00 03 00 00 00 03 00 00 00 03 00 00 00 03 00 00 00 03 00 00 00 05 00 00 00 05 00 00 00 06 00 00 00 06 00 00 00 06 00 00 00 07 00 00 00 07 00 00 00 08 00 00 00 80 00 00 00 03 00 00 00 90 01 00 00 90 01 00 00 90 01 00 00 90 01 00 00 f4 01 00 00 f4 01 00 00 f4 01 00 00 f4 01 00 00 20 00 00 00 1d 00 00 00 1d 00 00 00 1d 00 00 00 15 00 00 00 15 00 00 00 15 00 00 00 15 00 00 00 96 00 00 00 82 00 00 00 82 00 00 00 82 00 00 00 82 00 00 00 82 00 00 00 82 00 00 00 82 00 00 00 32 00 00 00 3c 00 00 00 40 00 00 00 42 00 00 00 44 00 00 00 44 00 00 00 46 00 00 00 46 00 00 00 1e 00 00 00 28 00 00 00 03 00 00 00 10 00 00 00 20 00 00 00 04 00 00 00 01 01 01 00 01 00 00 00 00 00 00 00 00 00 00 00 00 00 00 00 46 00 00 00 50 00 00 00 5a 00 00 00 64 00 00 00 32 00 00 00 10 00 00 00 e8 03 00 00 88 13 00 00 10 00 00 00 10 00 00 00 20 00 00 00 20 00 00 00 10 00 00 00 10 00 00 00 10 00 00 00 10 00 00 00 10 00 00 00 10 00 00 00 10 00 00 00 10 00 00 00 00 00 00 00 64 00 00 00 78 00 00 00 ff 00 00 00 20 00 00 00 00 00 00 00 00 00 00 00 05 00 00 00 08 00 00 00 0e 00 00 00 11 00 00 00 13 00 00 00 19 00 00 00 1c 00 00 00 80 00 00 00 40 00 00 00 00 00 00 00 03 00 00 00 08 00 00 00 0b 00 00 00 0d 00 00 00 10 00 00 00 10 00 00 00 11 00 00 00 80 00 00 00 40 00 00 00 00 00 00 00 00 00 00 00 00 00 00 00 80 00 00 00 80 00 00 00 00 00 00 00 00 01 00 00 00 01 00 00 00 01 00 00 00 02 00 00 00 02 00 00 04 00 00 00 04 00 00 00 03 00 00 00 04 00 00 00 04 00 00 00 04 00 00 00 04 00 00 00 04 00 00 00 08 00 00 00 09 00 00 00 09 00 00 00 0a 00 00 00 0a 00 00 00 0a 00 00 00 0b 00 00 00 0b 00 00 00 96 00 00 00 03 00 00 00 00 02 00 00 00 02 00 00 00 02 00 00 00 02 00 00 00 02 00 00 00 02 00 00 00 02 00 00 00 02 00 00 18 00 00 00 18 00 00 00 17 00 00 00 15 00 00 00 16 00 00 00 16 00 00 00 16 00 00 00 16 00 00 00 5a 00 00 00 5a 00 00 00 5a 00 00 00 5a 00 00 00 5a 00 00 00 5a 00 00 00 5a 00 00 00 5a 00 00 00 3c 00 00 00 3c 00 00 00 3c 00 00 00 3c 00 00 00 3c 00 00 00 3c 00 00 00 3c 00 00 00 3c 00 00 00 08 00 00 00 10 00 00 00 14 00 00 00 10 00 00 00 20 00 00 00 02 00 00 00 01 01 01 00 01 00 00 00 00 00 00 00 00 00 00 00 00 00 00 00 64 00 00 00 6e 00 00 00 78 00 00 00 82 00 00 00 80 00 00 00 40 00 00 00 b0 04 00 00 d0 07 00 00 14 00 00 00 10 00 00 00 10 00 00 00 10 00 00 00 14 00 00 00 18 00 00 00 18 00 00 00 10 00 00 00 10 00 00 00 10 00 00 00 10 00 00 00 10 00 00 00 00 00 00 00 20 00 00 00 80 00 00 00 ff 00 00 00 20 00 00 00 02 00 00 00 00 00 00 00 01 00 00 00 01 00 00 00 01 00 00 00 01 00 00 00 02 00 00 00 03 00 00 00 04 00 00 00 80 00 00 00 40 00 00 00 00 00 00 00 06 00 00 00 0b 00 00 00 0b 00 00 00 13 00 00 00 18 00 00 00 21 00 00 00 34 00 00 00 80 00 00 00 40 00 00 00 00 00 00 00 00 00 00 00 00 00 00 00 80 00 00 00 80 00 00 00 00 00 00 00 00 01 00 00 00 01 00 00 00 01 00 00 00 02 00 00 00 02 00 00 04 00 00 00 04 00 00 00 03 00 00 00 04 00 00 00 04 00 00 00 04 00 00 00 04 00 00 00 04 00 00 00 08 00 00 00 09 00 00 00 09 00 00 00 0a 00 00 00 0a 00 00 00 0a 00 00 00 0b 00 00 00 0b 00 00 00 96 00 00 00 03 00 00 00 00 02 00 00 00 02 00 00 00 02 00 00 00 02 00 00 00 02 00 00 00 02 00 00 00 02 00 00 00 02 00 00 18 00 00 00 18 00 00 00 17 00 00 00 15 00 00 00 16 00 00 00 16 00 00 00 16 00 00 00 16 00 00 00 5a 00 00 00 5a 00 00 00 5a 00 00 00 5a 00 00 00 5a 00 00 00 5a 00 00 00 5a 00 00 00 5a 00 00 00 3c 00 00 00 3c 00 00 00 3c 00 00 00 3c 00 00 00 3c 00 00 00 3c 00 00 00 3c 00 00 00 3c 00 00 00 08 00 00 00 10 00 00 00 14 00 00 00 10 00 00 00 20 00 00 00 02 00 00 00 01 01 01 00 01 00 00 00 00 00 00 00 00 00 00 00 00 00 00 00 64 00 00 00 6e 00 00 00 78 00 00 00 82 00 00 00 80 00 00 00 40 00 00 00 b0 04 00 00 d0 07 00 00 14 00 00 00 10 00 00 00 10 00 00 00 10 00 00 00 14 00 00 00 18 00 00 00 18 00 00 00 10 00 00 00 10 00 00 00 10 00 00 00 10 00 00 00 10 00 00 00 00 00 00 00 20 00 00 00 80 00 00 00 ff 00 00 00 20 00 00 00 02 00 00 00 00 00 00 00 01 00 00 00 01 00 00 00 01 00 00 00 01 00 00 00 02 00 00 00 03 00 00 00 04 00 00 00 80 00 00 00 40 00 00 00 00 00 00 00 06 00 00 00 0b 00 00 00 0b 00 00 00 13 00 00 00 18 00 00 00 21 00 00 00 34 00 00 00 80 00 00 00 40 00 00 00 00 00 00 00 00 00 00 00 00 00 00 00 80 00 00 00 80 00 00 00 00 00 00 00 00 01 00 00 00 01 00 00 00 01 00 00 00 02 00 00 00 02 00 00 04 00 00 00 04 00 00 00 03 00 00 00 04 00 00 00 04 00 00 00 04 00 00 00 04 00 00 00 04 00 00 00 08 00 00 00 09 00 00 00 09 00 00 00 0a 00 00 00 0a 00 00 00 0a 00 00 00 0b 00 00 00 0b 00 00 00 96 00 00 00 03 00 00 00 00 02 00 00 00 02 00 00 00 02 00 00 00 02 00 00 00 02 00 00 00 02 00 00 00 02 00 00 00 02 00 00 18 00 00 00 18 00 00 00 17 00 00 00 15 00 00 00 16 00 00 00 16 00 00 00 16 00 00 00 16 00 00 00 5a 00 00 00 5a 00 00 00 5a 00 00 00 5a 00 00 00 5a 00 00 00 5a 00 00 00 5a 00 00 00 5a 00 00 00 3c 00 00 00 3c 00 00 00 3c 00 00 00 3c 00 00 00 3c 00 00 00 3c 00 00 00 3c 00 00 00 3c 00 00 00 08 00 00 00 10 00 00 00 14 00 00 00 10 00 00 00 20 00 00 00 02 00 00 00 01 01 01 00 00 00 00 00 00 00 00 00 00 00 00 00 00 00 00 00 64 00 00 00 6e 00 00 00 78 00 00 00 82 00 00 00 80 00 00 00 40 00 00 00 b0 04 00 00 d0 07 00 00 14 00 00 00 10 00 00 00 10 00 00 00 10 00 00 00 14 00 00 00 18 00 00 00 18 00 00 00 10 00 00 00 10 00 00 00 10 00 00 00 10 00 00 00 10 00 00 00 00 00 00 00 20 00 00 00 80 00 00 00 ff 00 00 00 20 00 00 00 02 00 00 00 00 00 00 00 01 00 00 00 01 00 00 00 01 00 00 00 01 00 00 00 02 00 00 00 03 00 00 00 04 00 00 00 80 00 00 00 40 00 00 00 00 00 00 00 06 00 00 00 0b 00 00 00 0b 00 00 00 13 00 00 00 18 00 00 00 21 00 00 00 34 00 00 00 80 00 00 00 40 00 00 00 00 00 00 00];
		};
		iq_wdr {
			size = [e4 02 00 00];
			data = [01 00 00 00 00 00 00 00 20 00 00 00 12 00 00 00 80 00 00 00 05 00 00 00 03 00 00 00 00 00 00 00 08 00 00 00 10 00 00 00 18 00 00 00 1c 00 00 00 20 00 00 00 24 00 00 00 26 00 00 00 28 00 00 00 29 00 00 00 2a 00 00 00 2b 00 00 00 2c 00 00 00 2d 00 00 00 2e 00 00 00 2f 00 00 00 30 00 00 00 31 00 00 00 32 00 00 00 33 00 00 00 34 00 00 00 35 00 00 00 36 00 00 00 37 00 00 00 38 00 00 00 39 00 00 00 3a 00 00 00 3b 00 00 00 3c 00 00 00 3d 00 00 00 3e 00 00 00 3f 00 00 00 03 00 00 00 03 00 00 00 03 00 00 00 02 00 00 00 02 00 00 00 02 00 00 00 01 00 00 00 01 00 00 00 00 00 00 00 00 00 00 00 00 00 00 00 00 00 00 00 00 00 00 00 00 00 00 00 00 00 00 00 00 00 00 00 00 00 00 00 00 00 00 00 00 00 00 00 00 00 00 00 00 00 00 00 00 00 00 00 00 00 00 00 00 00 00 00 00 00 00 00 00 00 00 00 00 00 00 00 00 00 00 00 00 00 00 00 00 00 00 00 00 00 00 00 00 00 00 00 ff 0f 00 00 f7 0f 00 00 d8 0f 00 00 a1 0f 00 00 54 0f 00 00 f1 0e 00 00 7b 0e 00 00 f7 0d 00 00 68 0d 00 00 d1 0c 00 00 37 0c 00 00 9d 0b 00 00 04 0b 00 00 70 0a 00 00 e1 09 00 00 59 09 00 00 d8 08 00 00 5f 08 00 00 ee 07 00 00 84 07 00 00 22 07 00 00 c7 06 00 00 73 06 00 00 24 06 00 00 dc 05 00 00 5c 05 00 00 ee 04 00 00 90 04 00 00 3f 04 00 00 f9 03 00 00 bd 03 00 00 88 03 00 00 5b 03 00 00 32 03 00 00 0f 03 00 00 f0 02 00 00 d4 02 00 00 a6 02 00 00 80 02 00 00 62 02 00 00 49 02 00 00 23 02 00 00 08 02 00 00 f3 01 00 00 e4 01 00 00 d8 01 00 00 cf 01 00 00 c8 01 00 00 c2 01 00 00 bd 01 00 00 b9 01 00 00 b5 01 00 00 b2 01 00 00 b0 01 00 00 ae 01 00 00 ac 01 00 00 aa 01 00 00 a9 01 00 00 a7 01 00 00 a6 01 00 00 a5 01 00 00 a4 01 00 00 a4 01 00 00 a3 01 00 00 a2 01 00 00 40 00 00 00 50 00 00 00 00 00 00 00 ff 00 00 00 50 00 00 00 00 00 00 00 ff 00 00 00 50 00 00 00 00 00 00 00 ff 00 00 00 50 00 00 00 00 00 00 00 ff 00 00 00 50 00 00 00 00 00 00 00 ff 00 00 00 4c 00 00 00 00 00 00 00 ff 00 00 00 48 00 00 00 00 00 00 00 ff 00 00 00 44 00 00 00 00 00 00 00 ff 00 00 00 40 00 00 00 00 00 00 00 ff 00 00 00 40 00 00 00 00 00 00 00 ff 00 00 00 40 00 00 00 00 00 00 00 ff 00 00 00 40 00 00 00 00 00 00 00 ff 00 00 00 40 00 00 00 00 00 00 00 ff 00 00 00 40 00 00 00 00 00 00 00 ff 00 00 00 40 00 00 00 00 00 00 00 ff 00 00 00 40 00 00 00 00 00 00 00 ff 00 00 00];
		};
		iq_shdr {
			size = [ec 01 00 00];
			data = [00 00 00 00 00 00 00 00 01 00 00 00 a0 0c 09 00 ca 00 05 00 01 00 00 00 00 08 0a 00 80 00 07 00 02 00 00 02 04 08 0a 0c 0e 10 0e 0c 0a 08 06 04 02 00 00 00 00 00 00 00 04 00 08 10 18 1c 20 24 26 28 29 2a 2b 2c 2d 2e 2f 30 31 32 33 34 35 36 37 38 39 3a 3b 3c 3d 3e 3f 03 03 03 02 02 02 01 01 00 00 00 00 00 00 00 00 00 00 00 00 00 00 00 00 00 00 00 00 00 00 00 00 00 00 00 65 00 c3 00 1b 01 6d 01 bb 01 05 02 4a 02 8d 02 cc 02 08 03 42 03 79 03 af 03 e2 03 13 04 42 04 70 04 9d 04 c8 04 f1 04 1a 05 41 05 67 05 8c 05 d3 05 0f 06 42 06 6c 06 94 06 bc 06 e2 06 07 07 2b 07 4e 07 71 07 92 07 d3 07 12 08 4e 08 88 08 f7 08 61 09 c5 09 25 0a 81 0a da 0a 30 0b 84 0b d6 0b 25 0c 73 0c c0 0c 0b 0d 54 0d 9d 0d e4 0d 2a 0e 70 0e b4 0e f8 0e 3b 0f 7d 0f be 0f ff 0f e0 00 04 05 06 07 08 08 00 00 01 02 03 00 e0 00 04 05 06 07 08 08 00 00 01 02 03 00 e0 00 04 05 06 07 08 08 00 00 01 02 03 00 e0 00 04 05 06 07 08 08 00 00 01 02 03 00 e0 00 04 05 06 07 08 08 00 00 01 02 03 00 e0 00 04 05 06 07 08 08 00 00 01 02 03 00 e0 00 04 05 06 07 08 08 00 00 01 02 03 00 e0 00 04 05 06 07 08 08 00 00 01 02 03 00 e0 00 04 05 06 07 08 08 00 00 01 02 03 00 e0 00 04 05 06 07 08 08 00 00 01 02 03 00 e0 00 04 05 06 07 08 08 00 00 01 02 03 00 e0 00 04 05 06 07 08 08 00 00 01 02 03 00 e0 00 04 05 06 07 08 08 00 00 01 02 03 00 e0 00 04 05 06 07 08 08 00 00 01 02 03 00 e0 00 04 05 06 07 08 08 00 00 01 02 03 00 e0 00 04 05 06 07 08 08 00 00 01 02 03 00 e0 00 04 05 06 07 08 08 00 00 01 02 03 00 00 00];
		};
		iq_rgbir {
			size = [28 00 00 00];
			data = [00 00 00 00 cc 00 00 00 cc 00 00 00 e6 00 00 00 00 01 00 00 cc 00 00 00 cc 00 00 00 e6 00 00 00 dc 00 00 00 f0 00 00 00];
		};
		iq_companding {
			size = [18 01 00 00];
			data = [00 02 00 00 00 03 00 00 00 0a 00 00 ff 0f 00 00 ff 0f 00 00 ff 0f 00 00 ff 0f 00 00 ff 0f 00 00 ff 0f 00 00 ff 0f 00 00 ff 0f 00 00 00 00 00 00 00 01 00 00 00 02 00 00 00 08 00 00 00 08 00 00 00 08 00 00 00 08 00 00 00 08 00 00 00 08 00 00 00 08 00 00 00 08 00 00 00 08 00 00 04 00 00 00 05 00 00 00 06 00 00 00 08 00 00 00 08 00 00 00 08 00 00 00 08 00 00 00 08 00 00 00 08 00 00 00 08 00 00 00 08 00 00 00 08 00 00 00 0a 00 00 00 0b 00 00 00 0c 00 00 00 0d 00 00 00 0e 00 00 00 0f 00 00 00 10 00 00 00 10 00 00 00 10 00 00 00 10 00 00 00 10 00 00 00 00 00 00 00 00 02 00 00 00 04 00 00 00 06 00 00 00 08 00 00 00 0a 00 00 00 0c 00 00 00 0c 00 00 00 0c 00 00 00 0c 00 00 00 0c 00 00 00 0c 00 00 03 00 00 00 04 00 00 00 05 00 00 00 06 00 00 00 07 00 00 00 08 00 00 00 09 00 00 00 09 00 00 00 09 00 00 00 09 00 00 00 09 00 00 00 09 00 00 00];
		};
		iq_rgbir_enh {
			size = [18 01 00 00];
			data = [01 00 00 00 00 00 00 00 32 00 00 00 10 00 00 00 10 00 00 00 10 00 00 00 10 00 00 00 10 00 00 00 10 00 00 00 10 00 00 00 10 00 00 00 10 00 00 00 10 00 00 00 10 00 00 00 10 00 00 00 10 00 00 00 10 00 00 00 10 00 00 00 10 00 00 00 80 00 00 00 20 00 00 00 20 00 00 00 20 00 00 00 20 00 00 00 20 00 00 00 20 00 00 00 20 00 00 00 20 00 00 00 20 00 00 00 20 00 00 00 20 00 00 00 20 00 00 00 20 00 00 00 20 00 00 00 20 00 00 00 20 00 00 00 98 00 00 00 50 00 00 00 50 00 00 00 50 00 00 00 50 00 00 00 50 00 00 00 50 00 00 00 50 00 00 00 50 00 00 00 50 00 00 00 50 00 00 00 50 00 00 00 50 00 00 00 50 00 00 00 50 00 00 00 50 00 00 00 50 00 00 00 ff 00 00 00 a0 00 00 00 a0 00 00 00 a0 00 00 00 a0 00 00 00 a0 00 00 00 a0 00 00 00 a0 00 00 00 a0 00 00 00 a0 00 00 00 a0 00 00 00 a0 00 00 00 a0 00 00 00 a0 00 00 00 a0 00 00 00 a0 00 00 00 a0 00 00 00];
		};
		iq_post_sharpen {
			size = [4c 02 00 00];
			data = [01 00 00 00 00 00 00 00 19 23 23 23 23 23 23 23 23 23 23 23 23 23 23 23 23 23 02 af fa 00 5e 01 50 50 50 80 ff 00 40 80 80 00 19 23 23 23 23 23 23 23 23 23 23 23 23 23 23 23 23 23 02 af fa 00 5e 01 50 50 50 80 ff 00 40 80 80 00 19 23 23 23 23 23 23 23 23 23 23 23 23 23 23 23 23 23 02 af fa 00 5e 01 50 50 50 80 ff 00 40 80 80 00 19 23 23 23 23 23 23 23 23 23 23 23 23 23 23 23 23 23 02 af fa 00 5e 01 50 50 50 80 ff 00 40 80 80 00 19 23 23 23 23 23 23 23 23 23 23 23 23 23 23 23 23 23 02 af fa 00 5e 01 50 50 50 80 ff 00 40 80 80 00 19 23 23 23 23 23 23 23 23 23 23 23 23 23 23 23 23 23 02 af fa 00 5e 01 50 50 50 80 ff 00 40 80 80 00 19 23 23 23 23 23 23 23 23 23 23 23 23 23 23 23 23 23 02 af fa 00 5e 01 50 50 50 80 ff 00 40 80 80 00 19 23 23 23 23 23 23 23 23 23 23 23 23 23 23 23 23 23 02 af fa 00 5e 01 50 50 50 80 ff 00 40 80 80 00 19 23 23 23 23 23 23 23 23 23 23 23 23 23 23 23 23 23 02 af fa 00 5e 01 50 50 50 80 ff 00 40 80 80 00 19 23 23 23 23 23 23 23 23 23 23 23 23 23 23 23 23 23 02 af fa 00 5e 01 50 50 50 80 ff 00 40 80 80 00 19 23 23 23 23 23 23 23 23 23 23 23 23 23 23 23 23 23 02 af fa 00 5e 01 50 50 50 80 ff 00 40 80 80 00 19 23 23 23 23 23 23 23 23 23 23 23 23 23 23 23 23 23 02 af fa 00 5e 01 50 50 50 80 ff 00 40 80 80 00 19 23 23 23 23 23 23 23 23 23 23 23 23 23 23 23 23 23 02 af fa 00 5e 01 50 50 50 80 ff 00 40 80 80 00 19 23 23 23 23 23 23 23 23 23 23 23 23 23 23 23 23 23 02 af fa 00 5e 01 50 50 50 80 ff 00 40 80 80 00 19 23 23 23 23 23 23 23 23 23 23 23 23 23 23 23 23 23 02 af fa 00 5e 01 50 50 50 80 ff 00 40 80 80 00 19 23 23 23 23 23 23 23 23 23 23 23 23 23 23 23 23 23 02 af fa 00 5e 01 50 50 50 80 ff 00 40 80 80 00 19 23 23 23 23 23 23 23 23 23 23 23 23 23 23 23 23 23 02 af fa 00 5e 01 50 50 50 80 ff 00 40 80 80 00 00 00];
		};
	};
};
